AUTOSAR XML (schema 3.1.2)
package /Components/SWC_VSInfo
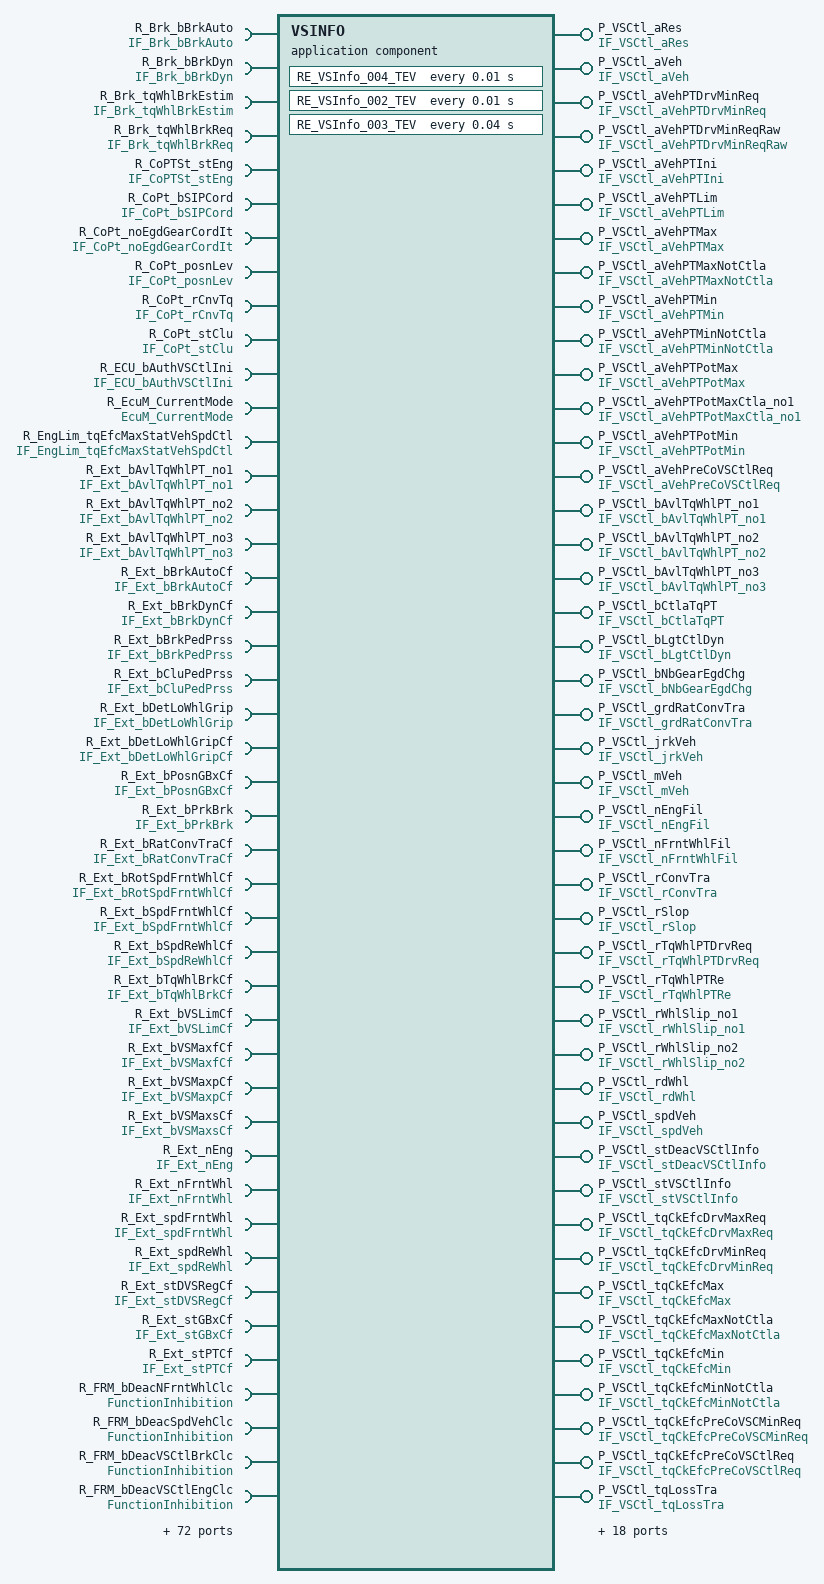
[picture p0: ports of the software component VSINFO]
  application software component type VSINFO  # VSInfo
    62 x provide port:
      P_VSCtl_aRes: unqueued-sender-com-spec{data-element=VSCtl_aRes, can-invalidate=false, init-value=ConstantValue}, provided-interface=IF_VSCtl_aRes
      P_VSCtl_aVeh: unqueued-sender-com-spec{data-element=VSCtl_aVeh, can-invalidate=false, init-value=C_SInt16_0}, provided-interface=IF_VSCtl_aVeh
      P_VSCtl_aVehPTDrvMinReq: unqueued-sender-com-spec{data-element=VSCtl_aVehPTDrvMinReq, can-invalidate=false, init-value=ConstantValue1}, provided-interface=IF_VSCtl_aVehPTDrvMinReq
      P_VSCtl_aVehPTDrvMinReqRaw: unqueued-sender-com-spec{data-element=VSCtl_aVehPTDrvMinReqRaw, can-invalidate=false, init-value=ConstantValue3}, provided-interface=IF_VSCtl_aVehPTDrvMinReqRaw
      P_VSCtl_aVehPTIni: unqueued-sender-com-spec{data-element=VSCtl_aVehPTIni, can-invalidate=false, init-value=C_SInt16_05}, provided-interface=IF_VSCtl_aVehPTIni
      P_VSCtl_aVehPTLim: unqueued-sender-com-spec{data-element=VSCtl_aVehPTLim, can-invalidate=false, init-value=ConstantValue7}, provided-interface=IF_VSCtl_aVehPTLim
      P_VSCtl_aVehPTMax: unqueued-sender-com-spec{data-element=VSCtl_aVehPTMax, can-invalidate=false, init-value=ConstantValue9}, provided-interface=IF_VSCtl_aVehPTMax
      P_VSCtl_aVehPTMaxNotCtla: unqueued-sender-com-spec{data-element=VSCtl_aVehPTMaxNotCtla, can-invalidate=false, init-value=ConstantValue11}, provided-interface=IF_VSCtl_aVehPTMaxNotCtla
      P_VSCtl_aVehPTMin: unqueued-sender-com-spec{data-element=VSCtl_aVehPTMin, can-invalidate=false, init-value=ConstantValue13}, provided-interface=IF_VSCtl_aVehPTMin
      P_VSCtl_aVehPTMinNotCtla: unqueued-sender-com-spec{data-element=VSCtl_aVehPTMinNotCtla, can-invalidate=false, init-value=ConstantValue15}, provided-interface=IF_VSCtl_aVehPTMinNotCtla
      P_VSCtl_aVehPTPotMax: unqueued-sender-com-spec{data-element=VSCtl_aVehPTPotMax, can-invalidate=false, init-value=ConstantValue17}, provided-interface=IF_VSCtl_aVehPTPotMax
      P_VSCtl_aVehPTPotMaxCtla_no1: unqueued-sender-com-spec{data-element=VSCtl_aVehPTPotMaxCtla_no1, can-invalidate=false, init-value=C_SInt16_10240}, provided-interface=IF_VSCtl_aVehPTPotMaxCtla_no1
      P_VSCtl_aVehPTPotMin: unqueued-sender-com-spec{data-element=VSCtl_aVehPTPotMin, can-invalidate=false, init-value=ConstantValue19}, provided-interface=IF_VSCtl_aVehPTPotMin
      P_VSCtl_aVehPreCoVSCtlReq: unqueued-sender-com-spec{data-element=VSCtl_aVehPreCoVSCtlReq, can-invalidate=false, init-value=ConstantValue21}, provided-interface=IF_VSCtl_aVehPreCoVSCtlReq
      P_VSCtl_bAvlTqWhlPT_no1: unqueued-sender-com-spec{data-element=VSCtl_bAvlTqWhlPT_no1, can-invalidate=false, init-value=C_Boolean_False}, provided-interface=IF_VSCtl_bAvlTqWhlPT_no1
      P_VSCtl_bAvlTqWhlPT_no2: unqueued-sender-com-spec{data-element=VSCtl_bAvlTqWhlPT_no2, can-invalidate=false, init-value=C_Boolean_False23}, provided-interface=IF_VSCtl_bAvlTqWhlPT_no2
      P_VSCtl_bAvlTqWhlPT_no3: unqueued-sender-com-spec{data-element=VSCtl_bAvlTqWhlPT_no3, can-invalidate=false, init-value=ConstantValue25}, provided-interface=IF_VSCtl_bAvlTqWhlPT_no3
      P_VSCtl_bCtlaTqPT: unqueued-sender-com-spec{data-element=VSCtl_bCtlaTqPT, can-invalidate=false, init-value=C_Boolean_False27}, provided-interface=IF_VSCtl_bCtlaTqPT
      P_VSCtl_bLgtCtlDyn: unqueued-sender-com-spec{data-element=VSCtl_bLgtCtlDyn, can-invalidate=false, init-value=C_Boolean_False29}, provided-interface=IF_VSCtl_bLgtCtlDyn
      P_VSCtl_bNbGearEgdChg: unqueued-sender-com-spec{data-element=VSCtl_bNbGearEgdChg, can-invalidate=false, init-value=C_Boolean_False31}, provided-interface=IF_VSCtl_bNbGearEgdChg
      P_VSCtl_grdRatConvTra: unqueued-sender-com-spec{data-element=VSCtl_grdRatConvTra, can-invalidate=false, init-value=C_SInt16_033}, provided-interface=IF_VSCtl_grdRatConvTra
      P_VSCtl_jrkVeh: unqueued-sender-com-spec{data-element=VSCtl_jrkVeh, can-invalidate=false, init-value=C_SInt16_035}, provided-interface=IF_VSCtl_jrkVeh
      P_VSCtl_mVeh: unqueued-sender-com-spec{data-element=VSCtl_mVeh, can-invalidate=false, init-value=ConstantValue37}, provided-interface=IF_VSCtl_mVeh
      P_VSCtl_nEngFil: unqueued-sender-com-spec{data-element=VSCtl_nEngFil, can-invalidate=false, init-value=C_UInt32_0}, provided-interface=IF_VSCtl_nEngFil
      P_VSCtl_nFrntWhlFil: unqueued-sender-com-spec{data-element=VSCtl_nFrntWhlFil, can-invalidate=false, init-value=C_UInt32_039}, provided-interface=IF_VSCtl_nFrntWhlFil
      P_VSCtl_rConvTra: unqueued-sender-com-spec{data-element=VSCtl_rConvTra, can-invalidate=false, init-value=C_UInt16_2560}, provided-interface=IF_VSCtl_rConvTra
      P_VSCtl_rSlop: unqueued-sender-com-spec{data-element=VSCtl_rSlop, can-invalidate=false, init-value=C_SInt16_041}, provided-interface=IF_VSCtl_rSlop
      P_VSCtl_rTqWhlPTDrvReq: unqueued-sender-com-spec{data-element=VSCtl_rTqWhlPTDrvReq, can-invalidate=false, init-value=C_UInt16_0}, provided-interface=IF_VSCtl_rTqWhlPTDrvReq
      P_VSCtl_rTqWhlPTRe: unqueued-sender-com-spec{data-element=VSCtl_rTqWhlPTRe, can-invalidate=false, init-value=C_UInt16_043}, provided-interface=IF_VSCtl_rTqWhlPTRe
      P_VSCtl_rWhlSlip_no1: unqueued-sender-com-spec{data-element=VSCtl_rWhlSlip_no1, can-invalidate=false, init-value=C_UInt16_045}, provided-interface=IF_VSCtl_rWhlSlip_no1
      P_VSCtl_rWhlSlip_no2: unqueued-sender-com-spec{data-element=VSCtl_rWhlSlip_no2, can-invalidate=false, init-value=C_UInt16_047}, provided-interface=IF_VSCtl_rWhlSlip_no2
      P_VSCtl_rdWhl: unqueued-sender-com-spec{data-element=VSCtl_rdWhl, can-invalidate=false, init-value=ConstantValue49}, provided-interface=IF_VSCtl_rdWhl
      P_VSCtl_spdVeh: unqueued-sender-com-spec{data-element=VSCtl_spdVeh, can-invalidate=false, init-value=ConstantValue51}, provided-interface=IF_VSCtl_spdVeh
      P_VSCtl_stDeacVSCtlInfo: unqueued-sender-com-spec{data-element=VSCtl_stDeacVSCtlInfo, can-invalidate=false, init-value=C_UInt8_32}, provided-interface=IF_VSCtl_stDeacVSCtlInfo
      P_VSCtl_stVSCtlInfo: unqueued-sender-com-spec{data-element=VSCtl_stVSCtlInfo, can-invalidate=false, init-value=ConstantValue53}, provided-interface=IF_VSCtl_stVSCtlInfo
      P_VSCtl_tqCkEfcDrvMaxReq: unqueued-sender-com-spec{data-element=VSCtl_tqCkEfcDrvMaxReq, can-invalidate=false, init-value=C_SInt16_32000}, provided-interface=IF_VSCtl_tqCkEfcDrvMaxReq
      P_VSCtl_tqCkEfcDrvMinReq: unqueued-sender-com-spec{data-element=VSCtl_tqCkEfcDrvMinReq, can-invalidate=false, init-value=C_SInt16_m32000}, provided-interface=IF_VSCtl_tqCkEfcDrvMinReq
      P_VSCtl_tqCkEfcMax: unqueued-sender-com-spec{data-element=VSCtl_tqCkEfcMax, can-invalidate=false, init-value=C_SInt16_3200055}, provided-interface=IF_VSCtl_tqCkEfcMax
      P_VSCtl_tqCkEfcMaxNotCtla: unqueued-sender-com-spec{data-element=VSCtl_tqCkEfcMaxNotCtla, can-invalidate=false, init-value=C_SInt16_057}, provided-interface=IF_VSCtl_tqCkEfcMaxNotCtla
      P_VSCtl_tqCkEfcMin: unqueued-sender-com-spec{data-element=VSCtl_tqCkEfcMin, can-invalidate=false, init-value=C_SInt16_m3200059}, provided-interface=IF_VSCtl_tqCkEfcMin
      P_VSCtl_tqCkEfcMinNotCtla: unqueued-sender-com-spec{data-element=VSCtl_tqCkEfcMinNotCtla, can-invalidate=false, init-value=C_SInt16_061}, provided-interface=IF_VSCtl_tqCkEfcMinNotCtla
      P_VSCtl_tqCkEfcPreCoVSCMinReq: unqueued-sender-com-spec{data-element=VSCtl_tqCkEfcPreCoVSCMinReq, can-invalidate=false, init-value=C_SInt16_m3200063}, provided-interface=IF_VSCtl_tqCkEfcPreCoVSCMinReq
      P_VSCtl_tqCkEfcPreCoVSCtlReq: unqueued-sender-com-spec{data-element=VSCtl_tqCkEfcPreCoVSCtlReq, can-invalidate=false, init-value=C_SInt16_m3200065}, provided-interface=IF_VSCtl_tqCkEfcPreCoVSCtlReq
      P_VSCtl_tqLossTra: unqueued-sender-com-spec{data-element=VSCtl_tqLossTra, can-invalidate=false, init-value=C_SInt16_067}, provided-interface=IF_VSCtl_tqLossTra
      P_VSCtl_tqWhlPTAplReq: unqueued-sender-com-spec{data-element=VSCtl_tqWhlPTAplReq, can-invalidate=false, init-value=C_SInt16_069}, provided-interface=IF_VSCtl_tqWhlPTAplReq
      P_VSCtl_tqWhlPTDrvMaxReq: unqueued-sender-com-spec{data-element=VSCtl_tqWhlPTDrvMaxReq, can-invalidate=false, init-value=C_SInt16_3200071}, provided-interface=IF_VSCtl_tqWhlPTDrvMaxReq
      P_VSCtl_tqWhlPTDrvMinReq: unqueued-sender-com-spec{data-element=VSCtl_tqWhlPTDrvMinReq, can-invalidate=false, init-value=C_SInt16_m3200073}, provided-interface=IF_VSCtl_tqWhlPTDrvMinReq
      P_VSCtl_tqWhlPTDrvMinReqRaw: unqueued-sender-com-spec{data-element=VSCtl_tqWhlPTDrvMinReqRaw, can-invalidate=false, init-value=C_SInt16_m3200075}, provided-interface=IF_VSCtl_tqWhlPTDrvMinReqRaw
      P_VSCtl_tqWhlPTMax: unqueued-sender-com-spec{data-element=VSCtl_tqWhlPTMax, can-invalidate=false, init-value=ConstantValue77}, provided-interface=IF_VSCtl_tqWhlPTMax
      P_VSCtl_tqWhlPTMaxNotCtla: unqueued-sender-com-spec{data-element=VSCtl_tqWhlPTMaxNotCtla, can-invalidate=false, init-value=C_SInt16_079}, provided-interface=IF_VSCtl_tqWhlPTMaxNotCtla
      P_VSCtl_tqWhlPTMin: unqueued-sender-com-spec{data-element=VSCtl_tqWhlPTMin, can-invalidate=false, init-value=ConstantValue81}, provided-interface=IF_VSCtl_tqWhlPTMin
      P_VSCtl_tqWhlPTMinNotCtla: unqueued-sender-com-spec{data-element=VSCtl_tqWhlPTMinNotCtla, can-invalidate=false, init-value=C_SInt16_083}, provided-interface=IF_VSCtl_tqWhlPTMinNotCtla
      P_VSCtl_tqWhlPTPotMax: unqueued-sender-com-spec{data-element=VSCtl_tqWhlPTPotMax, can-invalidate=false, init-value=ConstantValue85}, provided-interface=IF_VSCtl_tqWhlPTPotMax
      P_VSCtl_tqWhlPTPotMin: unqueued-sender-com-spec{data-element=VSCtl_tqWhlPTPotMin, can-invalidate=false, init-value=ConstantValue87}, provided-interface=IF_VSCtl_tqWhlPTPotMin
      P_VSCtl_tqWhlPTPotRawMax: unqueued-sender-com-spec{data-element=VSCtl_tqWhlPTPotRawMax, can-invalidate=false, init-value=C_SInt16_m3200089}, provided-interface=IF_VSCtl_tqWhlPTPotRawMax
      P_VSCtl_tqWhlPTPotRawMin: unqueued-sender-com-spec{data-element=VSCtl_tqWhlPTPotRawMin, can-invalidate=false, init-value=C_SInt16_m3200091}, provided-interface=IF_VSCtl_tqWhlPTPotRawMin
      P_VSCtl_tqWhlPTPreCoVSCMaxReq: unqueued-sender-com-spec{data-element=VSCtl_tqWhlPTPreCoVSCMaxReq, can-invalidate=false, init-value=C_SInt16_m3200093}, provided-interface=IF_VSCtl_tqWhlPTPreCoVSCMaxReq
      P_VSCtl_tqWhlPTPreCoVSCMinReq: unqueued-sender-com-spec{data-element=VSCtl_tqWhlPTPreCoVSCMinReq, can-invalidate=false, init-value=C_SInt16_m3200095}, provided-interface=IF_VSCtl_tqWhlPTPreCoVSCMinReq
      P_VSCtl_tqWhlPTPreCoVSCtlReq: unqueued-sender-com-spec{data-element=VSCtl_tqWhlPTPreCoVSCtlReq, can-invalidate=false, init-value=C_SInt16_m3200097}, provided-interface=IF_VSCtl_tqWhlPTPreCoVSCtlReq
      P_VSCtl_tqWhlPTReal: unqueued-sender-com-spec{data-element=VSCtl_tqWhlPTReal, can-invalidate=false, init-value=C_SInt16_099}, provided-interface=IF_VSCtl_tqWhlPTReal
      P_VSCtl_tqWhlThPTMin: unqueued-sender-com-spec{data-element=VSCtl_tqWhlThPTMin, can-invalidate=false, init-value=ConstantValue101}, provided-interface=IF_VSCtl_tqWhlThPTMin
      P_VSCtl_tqWhlThPTPotMin: unqueued-sender-com-spec{data-element=VSCtl_tqWhlThPTPotMin, can-invalidate=false, init-value=ConstantValue103}, provided-interface=IF_VSCtl_tqWhlThPTPotMin
    116 x require port:
      R_Brk_bBrkAuto: unqueued-receiver-com-spec{data-element=Brk_bBrkAuto, init-value=ConstantValue105, resync-time=0}, required-interface=IF_Brk_bBrkAuto
      R_Brk_bBrkDyn: unqueued-receiver-com-spec{data-element=Brk_bBrkDyn, init-value=C_Boolean_False107, resync-time=0}, required-interface=IF_Brk_bBrkDyn
      R_Brk_tqWhlBrkEstim: unqueued-receiver-com-spec{data-element=Brk_tqWhlBrkEstim, init-value=C_SInt16_m32000109, resync-time=0}, required-interface=IF_Brk_tqWhlBrkEstim
      R_Brk_tqWhlBrkReq: unqueued-receiver-com-spec{data-element=Brk_tqWhlBrkReq, init-value=C_SInt16_m32000111, resync-time=0}, required-interface=IF_Brk_tqWhlBrkReq
      R_CoPTSt_stEng: unqueued-receiver-com-spec{data-element=CoPTSt_stEng, init-value=ConstantValue113, resync-time=0}, required-interface=IF_CoPTSt_stEng
      R_CoPt_bSIPCord: unqueued-receiver-com-spec{data-element=CoPt_bSIPCord, init-value=ConstantValue115, resync-time=0}, required-interface=IF_CoPt_bSIPCord
      R_CoPt_noEgdGearCordIt: unqueued-receiver-com-spec{data-element=CoPt_noEgdGearCordIt, init-value=ConstantValue117, resync-time=0}, required-interface=IF_CoPt_noEgdGearCordIt
      R_CoPt_posnLev: unqueued-receiver-com-spec{data-element=CoPt_posnLev, init-value=ConstantValue119, resync-time=0}, required-interface=IF_CoPt_posnLev
      R_CoPt_rCnvTq: unqueued-receiver-com-spec{data-element=CoPt_rCnvTq, init-value=ConstantValue121, resync-time=0}, required-interface=IF_CoPt_rCnvTq
      R_CoPt_stClu: unqueued-receiver-com-spec{data-element=CoPt_stClu, init-value=ConstantValue123, resync-time=0}, required-interface=IF_CoPt_stClu
      R_ECU_bAuthVSCtlIni: unqueued-receiver-com-spec{data-element=ECU_bAuthVSCtlIni, init-value=C_Boolean_False125, resync-time=0}, required-interface=IF_ECU_bAuthVSCtlIni
      R_EcuM_CurrentMode: required-interface=EcuM_CurrentMode  # Requirement: 01552_09_00532-SSTG-C007(2)
      R_EngLim_tqEfcMaxStatVehSpdCtl: unqueued-receiver-com-spec{data-element=EngLim_tqEfcMaxStatVehSpdCtl, init-value=C_SInt16_m32000127, resync-time=0}, required-interface=IF_EngLim_tqEfcMaxStatVehSpdCtl
      R_Ext_bAvlTqWhlPT_no1: unqueued-receiver-com-spec{data-element=Ext_bAvlTqWhlPT_no1, init-value=C_Boolean_False129, resync-time=0}, required-interface=IF_Ext_bAvlTqWhlPT_no1
      R_Ext_bAvlTqWhlPT_no2: unqueued-receiver-com-spec{data-element=Ext_bAvlTqWhlPT_no2, init-value=C_Boolean_False131, resync-time=0}, required-interface=IF_Ext_bAvlTqWhlPT_no2
      R_Ext_bAvlTqWhlPT_no3: unqueued-receiver-com-spec{data-element=Ext_bAvlTqWhlPT_no3, init-value=C_Boolean_False133, resync-time=0}, required-interface=IF_Ext_bAvlTqWhlPT_no3
      R_Ext_bBrkAutoCf: unqueued-receiver-com-spec{data-element=Ext_bBrkAutoCf, init-value=C_Boolean_False135, resync-time=0}, required-interface=IF_Ext_bBrkAutoCf
      R_Ext_bBrkDynCf: unqueued-receiver-com-spec{data-element=Ext_bBrkDynCf, init-value=C_Boolean_False137, resync-time=0}, required-interface=IF_Ext_bBrkDynCf
      R_Ext_bBrkPedPrss: unqueued-receiver-com-spec{data-element=Ext_bBrkPedPrss, init-value=ConstantValue139, resync-time=0}, required-interface=IF_Ext_bBrkPedPrss
      R_Ext_bCluPedPrss: unqueued-receiver-com-spec{data-element=Ext_bCluPedPrss, init-value=ConstantValue141, resync-time=0}, required-interface=IF_Ext_bCluPedPrss
      R_Ext_bDetLoWhlGrip: unqueued-receiver-com-spec{data-element=Ext_bDetLoWhlGrip, init-value=C_Boolean_False143, resync-time=0}, required-interface=IF_Ext_bDetLoWhlGrip
      R_Ext_bDetLoWhlGripCf: unqueued-receiver-com-spec{data-element=Ext_bDetLoWhlGripCf, init-value=C_Boolean_False145, resync-time=0}, required-interface=IF_Ext_bDetLoWhlGripCf
      R_Ext_bPosnGBxCf: unqueued-receiver-com-spec{data-element=Ext_bPosnGBxCf, init-value=ConstantValue147, resync-time=0}, required-interface=IF_Ext_bPosnGBxCf
      R_Ext_bPrkBrk: unqueued-receiver-com-spec{data-element=Ext_bPrkBrk, init-value=C_Boolean_False149, resync-time=0}, required-interface=IF_Ext_bPrkBrk
      R_Ext_bRatConvTraCf: unqueued-receiver-com-spec{data-element=Ext_bRatConvTraCf, init-value=C_Boolean_False151, resync-time=0}, required-interface=IF_Ext_bRatConvTraCf
      R_Ext_bRotSpdFrntWhlCf: unqueued-receiver-com-spec{data-element=Ext_bRotSpdFrntWhlCf, init-value=C_Boolean_False153, resync-time=0}, required-interface=IF_Ext_bRotSpdFrntWhlCf
      R_Ext_bSpdFrntWhlCf: unqueued-receiver-com-spec{data-element=Ext_bSpdFrntWhlCf, init-value=C_Boolean_False155, resync-time=0}, required-interface=IF_Ext_bSpdFrntWhlCf
      R_Ext_bSpdReWhlCf: unqueued-receiver-com-spec{data-element=Ext_bSpdReWhlCf, init-value=C_Boolean_False157, resync-time=0}, required-interface=IF_Ext_bSpdReWhlCf
      R_Ext_bTqWhlBrkCf: unqueued-receiver-com-spec{data-element=Ext_bTqWhlBrkCf, init-value=C_Boolean_False159, resync-time=0}, required-interface=IF_Ext_bTqWhlBrkCf
      R_Ext_bVSLimCf: unqueued-receiver-com-spec{data-element=Ext_bVSLimCf, init-value=ConstantValue161, resync-time=0}, required-interface=IF_Ext_bVSLimCf
      R_Ext_bVSMaxfCf: unqueued-receiver-com-spec{data-element=Ext_bVSMaxfCf, init-value=ConstantValue163, resync-time=0}, required-interface=IF_Ext_bVSMaxfCf
      R_Ext_bVSMaxpCf: unqueued-receiver-com-spec{data-element=Ext_bVSMaxpCf, init-value=ConstantValue165, resync-time=0}, required-interface=IF_Ext_bVSMaxpCf
      R_Ext_bVSMaxsCf: unqueued-receiver-com-spec{data-element=Ext_bVSMaxsCf, init-value=ConstantValue167, resync-time=0}, required-interface=IF_Ext_bVSMaxsCf
      R_Ext_nEng: unqueued-receiver-com-spec{data-element=Ext_nEng, init-value=ConstantValue169, resync-time=0}, required-interface=IF_Ext_nEng
      R_Ext_nFrntWhl: unqueued-receiver-com-spec{data-element=Ext_nFrntWhl, init-value=C_UInt32_0171, resync-time=0}, required-interface=IF_Ext_nFrntWhl
      R_Ext_spdFrntWhl: unqueued-receiver-com-spec{data-element=Ext_spdFrntWhl, init-value=C_UInt16_0173, resync-time=0}, required-interface=IF_Ext_spdFrntWhl
      R_Ext_spdReWhl: unqueued-receiver-com-spec{data-element=Ext_spdReWhl, init-value=C_UInt16_0175, resync-time=0}, required-interface=IF_Ext_spdReWhl
      R_Ext_stDVSRegCf: unqueued-receiver-com-spec{data-element=Ext_stDVSRegCf, init-value=ConstantValue177, resync-time=0}, required-interface=IF_Ext_stDVSRegCf
      R_Ext_stGBxCf: unqueued-receiver-com-spec{data-element=Ext_stGBxCf, init-value=ConstantValue179, resync-time=0}, required-interface=IF_Ext_stGBxCf
      R_Ext_stPTCf: unqueued-receiver-com-spec{data-element=Ext_stPTCf, init-value=C_UInt8_0, resync-time=0}, required-interface=IF_Ext_stPTCf
      R_FRM_bDeacNFrntWhlClc: required-interface=FunctionInhibition
      R_FRM_bDeacSpdVehClc: required-interface=FunctionInhibition
      R_FRM_bDeacVSCtlBrkClc: required-interface=FunctionInhibition
      R_FRM_bDeacVSCtlEngClc: required-interface=FunctionInhibition
      R_FRM_bDeacVSCtlGrdLkClc: required-interface=FunctionInhibition
      R_FRM_bDeacVSCtlLoWhlGripClc: required-interface=FunctionInhibition
      R_FRM_bDeacVSCtlNoGearChgClc: required-interface=FunctionInhibition
      R_FRM_bDeacVSCtlPTClc: required-interface=FunctionInhibition
      R_FRM_bDeacVSCtlTraClc: required-interface=FunctionInhibition
      R_FRM_bDeacVSCtlVehClc: required-interface=FunctionInhibition
      R_FRM_bDeacVSCtlWhlSlipClc: required-interface=FunctionInhibition
      R_FRM_bDeacVSCtlrTqWhlPTReClc: required-interface=FunctionInhibition
      R_FRM_bRcvVSCtlSpdFrntWhl: required-interface=FunctionInhibition
      R_FRM_bRcvVSCtlSpdReWhl: required-interface=FunctionInhibition
      R_FRM_bRcvVSCtlrConvTra_Ext: required-interface=FunctionInhibition
      R_FRM_bRcvVSCtlrConvTra_Int1: required-interface=FunctionInhibition
      R_FRM_bRcvVSCtlrConvTra_Int2: required-interface=FunctionInhibition
      R_InjSys_bFuCutOff: unqueued-receiver-com-spec{data-element=InjSys_bFuCutOff, init-value=ConstantValue181, resync-time=0}, required-interface=IF_InjSys_bFuCutOff
      R_PtLim_tqWhlPTMaxCtla: unqueued-receiver-com-spec{data-element=PtLim_tqWhlPTMaxCtla, init-value=C_SInt16_m8000, resync-time=0}, required-interface=IF_PtLim_tqWhlPTMaxCtla
      R_PtLim_tqWhlPTMaxNotCtla: unqueued-receiver-com-spec{data-element=PtLim_tqWhlPTMaxNotCtla, init-value=C_SInt16_m8000183, resync-time=0}, required-interface=IF_PtLim_tqWhlPTMaxNotCtla
      R_PtLim_tqWhlPTMinCtla: unqueued-receiver-com-spec{data-element=PtLim_tqWhlPTMinCtla, init-value=C_SInt16_m8000185, resync-time=0}, required-interface=IF_PtLim_tqWhlPTMinCtla
      R_PtLim_tqWhlPTMinNotCtla: unqueued-receiver-com-spec{data-element=PtLim_tqWhlPTMinNotCtla, init-value=C_SInt16_m8000187, resync-time=0}, required-interface=IF_PtLim_tqWhlPTMinNotCtla
      R_PtLim_tqWhlPTPotMaxCtla_no1: unqueued-receiver-com-spec{data-element=PtLim_tqWhlPTPotMaxCtla_no1, init-value=C_SInt16_m8000189, resync-time=0}, required-interface=IF_PtLim_tqWhlPTPotMaxCtla_no1
      R_PtLim_tqWhlPTPotMaxCtla_no2: unqueued-receiver-com-spec{data-element=PtLim_tqWhlPTPotMaxCtla_no2, init-value=C_SInt16_m8000191, resync-time=0}, required-interface=IF_PtLim_tqWhlPTPotMaxCtla_no2
      R_PtLim_tqWhlPTPotMinCtla: unqueued-receiver-com-spec{data-element=PtLim_tqWhlPTPotMinCtla, init-value=C_SInt16_m8000193, resync-time=0}, required-interface=IF_PtLim_tqWhlPTPotMinCtla
      R_PtLim_tqWhlThPTMin: unqueued-receiver-com-spec{data-element=PtLim_tqWhlThPTMin, init-value=C_SInt16_m8000195, resync-time=0}, required-interface=IF_PtLim_tqWhlThPTMin
      R_PtLim_tqWhlThPTPotMin: unqueued-receiver-com-spec{data-element=PtLim_tqWhlThPTPotMin, init-value=C_SInt16_m8000197, resync-time=0}, required-interface=IF_PtLim_tqWhlThPTPotMin
      R_TqCmp_tqCnvLoss: unqueued-receiver-com-spec{data-element=TqCmp_tqCnvLoss, init-value=ConstantValue199, resync-time=0}, required-interface=IF_TqCmp_tqCnvLoss
      R_TqCmp_tqSumLossCmp: unqueued-receiver-com-spec{data-element=TqCmp_tqSumLossCmp, init-value=ConstantValue201, resync-time=0}, required-interface=IF_TqCmp_tqSumLossCmp
      R_TqDem_tqCkEfc: unqueued-receiver-com-spec{data-element=TqDem_tqCkEfc, init-value=ConstantValue203, resync-time=0}, required-interface=IF_TqDem_tqCkEfc
      R_TqDem_tqCkEfcMax: unqueued-receiver-com-spec{data-element=TqDem_tqCkEfcMax, init-value=ConstantValue205, resync-time=0}, required-interface=IF_TqDem_tqCkEfcMax
      R_TqDem_tqCkEfcMin: unqueued-receiver-com-spec{data-element=TqDem_tqCkEfcMin, init-value=ConstantValue207, resync-time=0}, required-interface=IF_TqDem_tqCkEfcMin
      R_TqDem_tqWhlPTDrvMaxReq: unqueued-receiver-com-spec{data-element=TqDem_tqWhlPTDrvMaxReq, init-value=C_SInt16_m8000209, resync-time=0}, required-interface=IF_TqDem_tqWhlPTDrvMaxReq
      R_TqDem_tqWhlPTDrvMinReq: unqueued-receiver-com-spec{data-element=TqDem_tqWhlPTDrvMinReq, init-value=C_SInt16_m8000211, resync-time=0}, required-interface=IF_TqDem_tqWhlPTDrvMinReq
      R_TqDem_tqWhlPTDrvMinReqRaw: unqueued-receiver-com-spec{data-element=TqDem_tqWhlPTDrvMinReqRaw, init-value=C_SInt16_m8000213, resync-time=0}, required-interface=IF_TqDem_tqWhlPTDrvMinReqRaw
      R_TqDem_tqWhlPTDrvReq: unqueued-receiver-com-spec{data-element=TqDem_tqWhlPTDrvReq, init-value=C_SInt16_m8000215, resync-time=0}, required-interface=IF_TqDem_tqWhlPTDrvReq
      R_TqDem_tqWhlPTPreCoVSCMaxReq: unqueued-receiver-com-spec{data-element=TqDem_tqWhlPTPreCoVSCMaxReq, init-value=C_SInt16_m8000217, resync-time=0}, required-interface=IF_TqDem_tqWhlPTPreCoVSCMaxReq
      R_TqDem_tqWhlPTPreCoVSCMinReq: unqueued-receiver-com-spec{data-element=TqDem_tqWhlPTPreCoVSCMinReq, init-value=C_SInt16_m8000219, resync-time=0}, required-interface=IF_TqDem_tqWhlPTPreCoVSCMinReq
      R_TqDem_tqWhlPTPreCoVSCtlReq: unqueued-receiver-com-spec{data-element=TqDem_tqWhlPTPreCoVSCtlReq, init-value=C_SInt16_m8000221, resync-time=0}, required-interface=IF_TqDem_tqWhlPTPreCoVSCtlReq
      R_TqSys_tqCkEfcMinFeas: unqueued-receiver-com-spec{data-element=TqSys_tqCkEfcMinFeas, init-value=ConstantValue223, resync-time=0}, required-interface=IF_TqSys_tqCkEfcMinFeas
      R_TqSys_tqCkEfcReq: unqueued-receiver-com-spec{data-element=TqSys_tqCkEfcReq, init-value=ConstantValue225, resync-time=0}, required-interface=IF_TqSys_tqCkEfcReq
      R_TqSys_tqCkEngReal: unqueued-receiver-com-spec{data-element=TqSys_tqCkEngReal, init-value=ConstantValue227, resync-time=0}, required-interface=IF_TqSys_tqCkEngReal
      R_UCE_stWkuMainRelSt: required-interface=IF_UCE_stWkuMainRelSt  # Requirement: 01552_09_00532-SSTG-C011(1)
      R_VSCtl_RatConvTraClc: required-interface=DiagnosticMonitor
      R_VSCtl_SpdVehClc: required-interface=DiagnosticMonitor
      R_VSCtl_aVehReq: unqueued-receiver-com-spec{data-element=VSCtl_aVehReq, init-value=ConstantValue229, resync-time=0}, required-interface=IF_VSCtl_aVehReq
      R_VSCtl_bAvlTqWhlPT_no3: unqueued-receiver-com-spec{data-element=VSCtl_bAvlTqWhlPT_no3, init-value=ConstantValue231, resync-time=0}, required-interface=IF_VSCtl_bAvlTqWhlPT_no3
      R_VSCtl_bCtlEfc_tqCkEfcMax: unqueued-receiver-com-spec{data-element=VSCtl_bCtlEfc_tqCkEfcMax, init-value=ConstantValue233, resync-time=0}, required-interface=IF_VSCtl_bCtlEfc_tqCkEfcMax
      R_VSCtl_bCtlEfc_tqWhlPTMax: unqueued-receiver-com-spec{data-element=VSCtl_bCtlEfc_tqWhlPTMax, init-value=ConstantValue235, resync-time=0}, required-interface=IF_VSCtl_bCtlEfc_tqWhlPTMax
      R_VSCtl_mVeh: unqueued-receiver-com-spec{data-element=VSCtl_mVeh, init-value=ConstantValue237, resync-time=0}, required-interface=IF_VSCtl_mVeh
      R_VSCtl_rSlop: unqueued-receiver-com-spec{data-element=VSCtl_rSlop, init-value=C_SInt16_m2560, resync-time=0}, required-interface=IF_VSCtl_rSlop
      R_VSCtl_rTqWhlPTRe: unqueued-receiver-com-spec{data-element=VSCtl_rTqWhlPTRe, init-value=C_UInt16_0239, resync-time=0}, required-interface=IF_VSCtl_rTqWhlPTRe
      R_VSCtl_rdWhl: unqueued-receiver-com-spec{data-element=VSCtl_rdWhl, init-value=ConstantValue241, resync-time=0}, required-interface=IF_VSCtl_rdWhl
      R_VSCtl_spdVeh: unqueued-receiver-com-spec{data-element=VSCtl_spdVeh, init-value=ConstantValue243, resync-time=0}, required-interface=IF_VSCtl_spdVeh
      R_VSCtl_tqWhlPTAplReq: unqueued-receiver-com-spec{data-element=VSCtl_tqWhlPTAplReq, init-value=C_SInt16_m8000245, resync-time=0}, required-interface=IF_VSCtl_tqWhlPTAplReq
      R_VSCtl_tqWhlPTDrvMinReq: unqueued-receiver-com-spec{data-element=VSCtl_tqWhlPTDrvMinReq, init-value=C_SInt16_m32000247, resync-time=0}, required-interface=IF_VSCtl_tqWhlPTDrvMinReq
      R_VSCtl_tqWhlPTDrvMinReqRaw: unqueued-receiver-com-spec{data-element=VSCtl_tqWhlPTDrvMinReqRaw, init-value=C_SInt16_m32000249, resync-time=0}, required-interface=IF_VSCtl_tqWhlPTDrvMinReqRaw
      R_VSCtl_tqWhlPTMax: unqueued-receiver-com-spec{data-element=VSCtl_tqWhlPTMax, init-value=ConstantValue251, resync-time=0}, required-interface=IF_VSCtl_tqWhlPTMax
      R_VSCtl_tqWhlPTMaxNotCtla: unqueued-receiver-com-spec{data-element=VSCtl_tqWhlPTMaxNotCtla, init-value=C_SInt16_m32000253, resync-time=0}, required-interface=IF_VSCtl_tqWhlPTMaxNotCtla
      R_VSCtl_tqWhlPTMin: unqueued-receiver-com-spec{data-element=VSCtl_tqWhlPTMin, init-value=ConstantValue255, resync-time=0}, required-interface=IF_VSCtl_tqWhlPTMin
      R_VSCtl_tqWhlPTMinNotCtla: unqueued-receiver-com-spec{data-element=VSCtl_tqWhlPTMinNotCtla, init-value=C_SInt16_m32000257, resync-time=0}, required-interface=IF_VSCtl_tqWhlPTMinNotCtla
      R_VSCtl_tqWhlPTPotMax: unqueued-receiver-com-spec{data-element=VSCtl_tqWhlPTPotMax, init-value=ConstantValue259, resync-time=0}, required-interface=IF_VSCtl_tqWhlPTPotMax
      R_VSCtl_tqWhlPTPotMin: unqueued-receiver-com-spec{data-element=VSCtl_tqWhlPTPotMin, init-value=ConstantValue261, resync-time=0}, required-interface=IF_VSCtl_tqWhlPTPotMin
      R_VSCtl_tqWhlPTPreCoVSCtlReq: unqueued-receiver-com-spec{data-element=VSCtl_tqWhlPTPreCoVSCtlReq, init-value=C_SInt16_m32000263, resync-time=0}, required-interface=IF_VSCtl_tqWhlPTPreCoVSCtlReq
      R_VSCtl_tqWhlPTReal: unqueued-receiver-com-spec{data-element=VSCtl_tqWhlPTReal, init-value=C_SInt16_m8000265, resync-time=0}, required-interface=IF_VSCtl_tqWhlPTReal
      R_VSCtl_tqWhlPotMaxRsvHiThd: unqueued-receiver-com-spec{data-element=VSCtl_tqWhlPotMaxRsvHiThd, init-value=ConstantValue267, resync-time=0}, required-interface=IF_VSCtl_tqWhlPotMaxRsvHiThd
      R_VSCtl_tqWhlPotMaxRsvLoThd: unqueued-receiver-com-spec{data-element=VSCtl_tqWhlPotMaxRsvLoThd, init-value=ConstantValue269, resync-time=0}, required-interface=IF_VSCtl_tqWhlPotMaxRsvLoThd
      R_VSCtl_tqWhlPotMinRsvHiThd: unqueued-receiver-com-spec{data-element=VSCtl_tqWhlPotMinRsvHiThd, init-value=ConstantValue271, resync-time=0}, required-interface=IF_VSCtl_tqWhlPotMinRsvHiThd
      R_VSCtl_tqWhlPotMinRsvLoThd: unqueued-receiver-com-spec{data-element=VSCtl_tqWhlPotMinRsvLoThd, init-value=ConstantValue273, resync-time=0}, required-interface=IF_VSCtl_tqWhlPotMinRsvLoThd
      R_VSInfo_GetTimer_1ms_U32: required-interface=IF_CS_FRunTime_1MS_U32
      R_VehEst_bCtlTqWhlPT: unqueued-receiver-com-spec{data-element=VehEst_bCtlTqWhlPT, init-value=C_Boolean_False275, resync-time=0}, required-interface=IF_VehEst_bCtlTqWhlPT
      R_VehEst_rTqWhlPTRe: unqueued-receiver-com-spec{data-element=VehEst_rTqWhlPTRe, init-value=C_UInt16_0277, resync-time=0}, required-interface=IF_VehEst_rTqWhlPTRe
      R_VehEst_tqWhlPTRealEstim: unqueued-receiver-com-spec{data-element=VehEst_tqWhlPTRealEstim, init-value=C_SInt16_m8000279, resync-time=0}, required-interface=IF_VehEst_tqWhlPTRealEstim
      R_VehEst_tqWhlPTReq: unqueued-receiver-com-spec{data-element=VehEst_tqWhlPTReq, init-value=C_SInt16_m8000281, resync-time=0}, required-interface=IF_VehEst_tqWhlPTReq
      R_Veh_spdVeh: unqueued-receiver-com-spec{data-element=Veh_spdVeh, init-value=ConstantValue283, resync-time=0}, required-interface=IF_Veh_spdVeh
      R_Ext_bCtlCmdPTTqCf: unqueued-receiver-com-spec{data-element=Ext_bCtlCmdPTTqCf, init-value=ConstantValue285, resync-time=0}, required-interface=IF_Ext_bCtlCmdPTTqCf  # R_Ext_bVSMaxpCf
  167 x constant specification:
    C_Boolean_False
      value:
        boolean literal C_Boolean_False: type=DT_VSCtl_bAvlTqWhlPT_no1, value=false
    C_Boolean_False107
      value:
        boolean literal C_Boolean_False107: type=DT_Brk_bBrkDyn, value=false
    C_Boolean_False125
      value:
        boolean literal C_Boolean_False125: type=DT_ECU_bAuthVSCtlIni, value=false
    C_Boolean_False129
      value:
        boolean literal C_Boolean_False129: type=DT_Ext_bAvlTqWhlPT_no1, value=false
    C_Boolean_False131
      value:
        boolean literal C_Boolean_False131: type=DT_Ext_bAvlTqWhlPT_no2, value=false
    C_Boolean_False133
      value:
        boolean literal C_Boolean_False133: type=DT_Ext_bAvlTqWhlPT_no3, value=false
    C_Boolean_False135
      value:
        boolean literal C_Boolean_False135: type=DT_Ext_bBrkAutoCf, value=false
    C_Boolean_False137
      value:
        boolean literal C_Boolean_False137: type=DT_Ext_bBrkDynCf, value=false
    C_Boolean_False143
      value:
        boolean literal C_Boolean_False143: type=DT_Ext_bDetLoWhlGrip, value=false
    C_Boolean_False145
      value:
        boolean literal C_Boolean_False145: type=DT_Ext_bDetLoWhlGripCf, value=false
    C_Boolean_False149
      value:
        boolean literal C_Boolean_False149: type=DT_Ext_bPrkBrk, value=false
    C_Boolean_False151
      value:
        boolean literal C_Boolean_False151: type=DT_Ext_bRatConvTraCf, value=false
    C_Boolean_False153
      value:
        boolean literal C_Boolean_False153: type=DT_Ext_bRotSpdFrntWhlCf, value=false
    C_Boolean_False155
      value:
        boolean literal C_Boolean_False155: type=DT_Ext_bSpdFrntWhlCf, value=false
    C_Boolean_False157
      value:
        boolean literal C_Boolean_False157: type=DT_Ext_bSpdReWhlCf, value=false
    C_Boolean_False159
      value:
        boolean literal C_Boolean_False159: type=DT_Ext_bTqWhlBrkCf, value=false
    C_Boolean_False23
      value:
        boolean literal C_Boolean_False23: type=DT_VSCtl_bAvlTqWhlPT_no2, value=false
    C_Boolean_False27
      value:
        boolean literal C_Boolean_False27: type=DT_VSCtl_bCtlaTqPT, value=false
    C_Boolean_False275
      value:
        boolean literal C_Boolean_False275: type=DT_VehEst_bCtlTqWhlPT, value=false
    C_Boolean_False29
      value:
        boolean literal C_Boolean_False29: type=DT_VSCtl_bLgtCtlDyn, value=false
    C_Boolean_False31
      value:
        boolean literal C_Boolean_False31: type=DT_VSCtl_bNbGearEgdChg, value=false
    C_SInt16_0
      value:
        integer literal C_SInt16_0: type=DT_VSCtl_aVeh, value=0
    C_SInt16_0287
      value:
        integer literal C_SInt16_0287: type=DT_VSCtl_aAero, value=0
    C_SInt16_0291
      value:
        integer literal C_SInt16_0291: type=DT_VSCtl_tqWhlPTIni, value=0
    C_SInt16_0297
      value:
        integer literal C_SInt16_0297: type=DT_VSCtl_tqWhlBrkEstim, value=0
    C_SInt16_0299
      value:
        integer literal C_SInt16_0299: type=DT_VSCtl_tqWhlBrkReq, value=0
    C_SInt16_033
      value:
        integer literal C_SInt16_033: type=DT_VSCtl_grdRatConvTra, value=0
    C_SInt16_035
      value:
        integer literal C_SInt16_035: type=DT_VSCtl_jrkVeh, value=0
    C_SInt16_041
      value:
        integer literal C_SInt16_041: type=DT_VSCtl_rSlop, value=0
    C_SInt16_05
      value:
        integer literal C_SInt16_05: type=DT_VSCtl_aVehPTIni, value=0
    C_SInt16_057
      value:
        integer literal C_SInt16_057: type=DT_VSCtl_tqCkEfcMaxNotCtla, value=0
    C_SInt16_061
      value:
        integer literal C_SInt16_061: type=DT_VSCtl_tqCkEfcMinNotCtla, value=0
    C_SInt16_067
      value:
        integer literal C_SInt16_067: type=DT_VSCtl_tqLossTra, value=0
    C_SInt16_069
      value:
        integer literal C_SInt16_069: type=DT_VSCtl_tqWhlPTAplReq, value=0
    C_SInt16_079
      value:
        integer literal C_SInt16_079: type=DT_VSCtl_tqWhlPTMaxNotCtla, value=0
    C_SInt16_083
      value:
        integer literal C_SInt16_083: type=DT_VSCtl_tqWhlPTMinNotCtla, value=0
    C_SInt16_099
      value:
        integer literal C_SInt16_099: type=DT_VSCtl_tqWhlPTReal, value=0
    C_SInt16_10240
      value:
        integer literal C_SInt16_10240: type=DT_VSCtl_aVehPTPotMaxCtla_no1, value=10240
    C_SInt16_32000
      value:
        integer literal C_SInt16_32000: type=DT_VSCtl_tqCkEfcDrvMaxReq, value=32000
    C_SInt16_32000295
      value:
        integer literal C_SInt16_32000295: type=DT_VSCtl_tqWhlPTPotMaxCtla_no1, value=32000
    C_SInt16_3200055
      value:
        integer literal C_SInt16_3200055: type=DT_VSCtl_tqCkEfcMax, value=32000
    C_SInt16_3200071
      value:
        integer literal C_SInt16_3200071: type=DT_VSCtl_tqWhlPTDrvMaxReq, value=32000
    C_SInt16_m2560
      value:
        integer literal C_SInt16_m2560: type=DT_VSCtl_rSlop, value=0
    C_SInt16_m32000
      value:
        integer literal C_SInt16_m32000: type=DT_VSCtl_tqCkEfcDrvMinReq, value=-32000
    C_SInt16_m32000109
      value:
        integer literal C_SInt16_m32000109: type=DT_Brk_tqWhlBrkEstim, value=0
    C_SInt16_m32000111
      value:
        integer literal C_SInt16_m32000111: type=DT_Brk_tqWhlBrkReq, value=0
    C_SInt16_m32000127
      value:
        integer literal C_SInt16_m32000127: type=DT_EngLim_tqEfcMaxStatVehSpdCtl, value=32000
    C_SInt16_m32000247
      value:
        integer literal C_SInt16_m32000247: type=DT_VSCtl_tqWhlPTDrvMinReq, value=0
    C_SInt16_m32000249
      value:
        integer literal C_SInt16_m32000249: type=DT_VSCtl_tqWhlPTDrvMinReqRaw, value=0
    C_SInt16_m32000253
      value:
        integer literal C_SInt16_m32000253: type=DT_VSCtl_tqWhlPTMaxNotCtla, value=0
    C_SInt16_m32000257
      value:
        integer literal C_SInt16_m32000257: type=DT_VSCtl_tqWhlPTMinNotCtla, value=0
    C_SInt16_m32000263
      value:
        integer literal C_SInt16_m32000263: type=DT_VSCtl_tqWhlPTPreCoVSCtlReq, value=0
    C_SInt16_m32000305
      value:
        integer literal C_SInt16_m32000305: type=DT_VSCtl_tqWhlPTLim, value=-32000
    C_SInt16_m3200059
      value:
        integer literal C_SInt16_m3200059: type=DT_VSCtl_tqCkEfcMin, value=-32000
    C_SInt16_m3200063
      value:
        integer literal C_SInt16_m3200063: type=DT_VSCtl_tqCkEfcPreCoVSCMinReq, value=-32000
    C_SInt16_m3200065
      value:
        integer literal C_SInt16_m3200065: type=DT_VSCtl_tqCkEfcPreCoVSCtlReq, value=4000
    C_SInt16_m3200073
      value:
        integer literal C_SInt16_m3200073: type=DT_VSCtl_tqWhlPTDrvMinReq, value=0
    C_SInt16_m3200075
      value:
        integer literal C_SInt16_m3200075: type=DT_VSCtl_tqWhlPTDrvMinReqRaw, value=0
    C_SInt16_m3200089
      value:
        integer literal C_SInt16_m3200089: type=DT_VSCtl_tqWhlPTPotRawMax, value=-32000
    C_SInt16_m3200091
      value:
        integer literal C_SInt16_m3200091: type=DT_VSCtl_tqWhlPTPotRawMin, value=-32000
    C_SInt16_m3200093
      value:
        integer literal C_SInt16_m3200093: type=DT_VSCtl_tqWhlPTPreCoVSCMaxReq, value=-32000
    C_SInt16_m3200095
      value:
        integer literal C_SInt16_m3200095: type=DT_VSCtl_tqWhlPTPreCoVSCMinReq, value=-32000
    C_SInt16_m3200097
      value:
        integer literal C_SInt16_m3200097: type=DT_VSCtl_tqWhlPTPreCoVSCtlReq, value=0
    C_SInt16_m8000
      value:
        integer literal C_SInt16_m8000: type=DT_PtLim_tqWhlPTMaxCtla, value=0
    C_SInt16_m8000183
      value:
        integer literal C_SInt16_m8000183: type=DT_PtLim_tqWhlPTMaxNotCtla, value=0
    C_SInt16_m8000185
      value:
        integer literal C_SInt16_m8000185: type=DT_PtLim_tqWhlPTMinCtla, value=0
    C_SInt16_m8000187
      value:
        integer literal C_SInt16_m8000187: type=DT_PtLim_tqWhlPTMinNotCtla, value=0
    C_SInt16_m8000189
      value:
        integer literal C_SInt16_m8000189: type=DT_PtLim_tqWhlPTPotMaxCtla_no1, value=0
    C_SInt16_m8000191
      value:
        integer literal C_SInt16_m8000191: type=DT_PtLim_tqWhlPTPotMaxCtla_no2, value=0
    C_SInt16_m8000193
      value:
        integer literal C_SInt16_m8000193: type=DT_PtLim_tqWhlPTPotMinCtla, value=0
    C_SInt16_m8000195
      value:
        integer literal C_SInt16_m8000195: type=DT_PtLim_tqWhlThPTMin, value=0
    C_SInt16_m8000197
      value:
        integer literal C_SInt16_m8000197: type=DT_PtLim_tqWhlThPTPotMin, value=0
    C_SInt16_m8000209
      value:
        integer literal C_SInt16_m8000209: type=DT_TqDem_tqWhlPTDrvMaxReq, value=0
    C_SInt16_m8000211
      value:
        integer literal C_SInt16_m8000211: type=DT_TqDem_tqWhlPTDrvMinReq, value=0
    C_SInt16_m8000213
      value:
        integer literal C_SInt16_m8000213: type=DT_TqDem_tqWhlPTDrvMinReqRaw, value=0
    C_SInt16_m8000215
      value:
        integer literal C_SInt16_m8000215: type=DT_TqDem_tqWhlPTDrvReq, value=0
    C_SInt16_m8000217
      value:
        integer literal C_SInt16_m8000217: type=DT_TqDem_tqWhlPTPreCoVSCMaxReq, value=0
    C_SInt16_m8000219
      value:
        integer literal C_SInt16_m8000219: type=DT_TqDem_tqWhlPTPreCoVSCMinReq, value=0
    C_SInt16_m8000221
      value:
        integer literal C_SInt16_m8000221: type=DT_TqDem_tqWhlPTPreCoVSCtlReq, value=0
    C_SInt16_m8000245
      value:
        integer literal C_SInt16_m8000245: type=DT_VSCtl_tqWhlPTAplReq, value=0
    C_SInt16_m8000265
      value:
        integer literal C_SInt16_m8000265: type=DT_VSCtl_tqWhlPTReal, value=0
    C_SInt16_m8000279
      value:
        integer literal C_SInt16_m8000279: type=DT_VehEst_tqWhlPTRealEstim, value=0
    C_SInt16_m8000281
      value:
        integer literal C_SInt16_m8000281: type=DT_VehEst_tqWhlPTReq, value=0
    C_UInt16_0
      value:
        integer literal C_UInt16_0: type=DT_VSCtl_rTqWhlPTDrvReq, value=0
    C_UInt16_0173
      value:
        integer literal C_UInt16_0173: type=DT_Ext_spdFrntWhl, value=0
    C_UInt16_0175
      value:
        integer literal C_UInt16_0175: type=DT_Ext_spdReWhl, value=0
    C_UInt16_0239
      value:
        integer literal C_UInt16_0239: type=DT_VSCtl_rTqWhlPTRe, value=0
    C_UInt16_0277
      value:
        integer literal C_UInt16_0277: type=DT_VehEst_rTqWhlPTRe, value=0
    C_UInt16_0307
      value:
        integer literal C_UInt16_0307: type=DT_VSCtl_spdVehRef, value=0
    C_UInt16_043
      value:
        integer literal C_UInt16_043: type=DT_VSCtl_rTqWhlPTRe, value=0
    C_UInt16_045
      value:
        integer literal C_UInt16_045: type=DT_VSCtl_rWhlSlip_no1, value=0
    C_UInt16_047
      value:
        integer literal C_UInt16_047: type=DT_VSCtl_rWhlSlip_no2, value=0
    C_UInt16_2560
      value:
        integer literal C_UInt16_2560: type=DT_VSCtl_rConvTra, value=2560
    C_UInt32_0
      value:
        integer literal C_UInt32_0: type=DT_VSCtl_nEngFil, value=0
    C_UInt32_0171
      value:
        integer literal C_UInt32_0171: type=DT_Ext_nFrntWhl, value=0
    C_UInt32_039
      value:
        integer literal C_UInt32_039: type=DT_VSCtl_nFrntWhlFil, value=0
    C_UInt8_0
      value:
        integer literal C_UInt8_0: type=DT_Ext_stPTCf, value=0
    C_UInt8_0289
      value:
        integer literal C_UInt8_0289: type=DT_VSCtl_stVehInfo, value=0
    C_UInt8_0293
      value:
        integer literal C_UInt8_0293: type=DT_VSCtl_stGrdLkInfo, value=0
    C_UInt8_0301
      value:
        integer literal C_UInt8_0301: type=DT_VSCtl_stPTInfo, value=0
    C_UInt8_0303
      value:
        integer literal C_UInt8_0303: type=DT_VSCtl_stDiagSpdVeh, value=0
    C_UInt8_32
      value:
        integer literal C_UInt8_32: type=DT_VSCtl_stDeacVSCtlInfo, value=32
    ConstantValue
      value:
        integer literal ConstantValue: type=DT_VSCtl_aRes, value=0
    ConstantValue1
      value:
        integer literal ConstantValue1: type=DT_VSCtl_aVehPTDrvMinReq, value=0
    ConstantValue101
      value:
        integer literal ConstantValue101: type=DT_VSCtl_tqWhlThPTMin, value=0
    ConstantValue103
      value:
        integer literal ConstantValue103: type=DT_VSCtl_tqWhlThPTPotMin, value=0
    ConstantValue105
      value:
        boolean literal ConstantValue105: type=DT_Brk_bBrkAuto, value=false
    ConstantValue11
      value:
        integer literal ConstantValue11: type=DT_VSCtl_aVehPTMaxNotCtla, value=0
    ConstantValue113
      value:
        integer literal ConstantValue113: type=DT_CoPTSt_stEng, value=1
    ConstantValue115
      value:
        boolean literal ConstantValue115: type=DT_CoPt_bSIPCord, value=false
    ConstantValue117
      value:
        integer literal ConstantValue117: type=DT_CoPt_noEgdGearCordIt, value=0
    ConstantValue119
      value:
        integer literal ConstantValue119: type=DT_CoPt_posnLev, value=0
    ConstantValue121
      value:
        integer literal ConstantValue121: type=DT_CoPt_rCnvTq, value=1
    ConstantValue123
      value:
        integer literal ConstantValue123: type=DT_CoPt_stClu, value=0
    ConstantValue13
      value:
        integer literal ConstantValue13: type=DT_VSCtl_aVehPTMin, value=0
    ConstantValue139
      value:
        boolean literal ConstantValue139: type=DT_Ext_bBrkPedPrss, value=false
    ConstantValue141
      value:
        boolean literal ConstantValue141: type=DT_Ext_bCluPedPrss, value=false
    ConstantValue147
      value:
        boolean literal ConstantValue147: type=DT_Ext_bPosnGBxCf, value=false
    ConstantValue15
      value:
        integer literal ConstantValue15: type=DT_VSCtl_aVehPTMinNotCtla, value=0
    ConstantValue161
      value:
        boolean literal ConstantValue161: type=DT_Ext_bVSLimCf, value=false
    ConstantValue163
      value:
        boolean literal ConstantValue163: type=DT_Ext_bVSMaxfCf, value=false
    ConstantValue165
      value:
        boolean literal ConstantValue165: type=DT_Ext_bVSMaxpCf, value=false
    ConstantValue167
      value:
        boolean literal ConstantValue167: type=DT_Ext_bVSMaxsCf, value=false
    ConstantValue169
      value:
        integer literal ConstantValue169: type=DT_Ext_nEng, value=0
    ConstantValue17
      value:
        integer literal ConstantValue17: type=DT_VSCtl_aVehPTPotMax, value=0
    ConstantValue177
      value:
        integer literal ConstantValue177: type=DT_Ext_stDVSRegCf, value=0
    ConstantValue179
      value:
        integer literal ConstantValue179: type=DT_Ext_stGBxCf, value=0
    ConstantValue181
      value:
        boolean literal ConstantValue181: type=DT_InjSys_bFuCutOff, value=false
    ConstantValue19
      value:
        integer literal ConstantValue19: type=DT_VSCtl_aVehPTPotMin, value=0
    ConstantValue199
      value:
        integer literal ConstantValue199: type=DT_TqCmp_tqCnvLoss, value=0
    ConstantValue201
      value:
        integer literal ConstantValue201: type=DT_TqCmp_tqSumLossCmp, value=0
    ConstantValue203
      value:
        integer literal ConstantValue203: type=DT_TqDem_tqCkEfc, value=0
    ConstantValue205
      value:
        integer literal ConstantValue205: type=DT_TqDem_tqCkEfcMax, value=0
    ConstantValue207
      value:
        integer literal ConstantValue207: type=DT_TqDem_tqCkEfcMin, value=0
    ConstantValue21
      value:
        integer literal ConstantValue21: type=DT_VSCtl_aVehPreCoVSCtlReq, value=0
    ConstantValue223
      value:
        integer literal ConstantValue223: type=DT_TqSys_tqCkEfcMinFeas, value=0
    ConstantValue225
      value:
        integer literal ConstantValue225: type=DT_TqSys_tqCkEfcReq, value=0
    ConstantValue227
      value:
        integer literal ConstantValue227: type=DT_TqSys_tqCkEngReal, value=0
    ConstantValue229
      value:
        integer literal ConstantValue229: type=DT_VSCtl_aVehReq, value=-10240
    ConstantValue231
      value:
        boolean literal ConstantValue231: type=DT_VSCtl_bAvlTqWhlPT_no3, value=false
    ConstantValue233
      value:
        boolean literal ConstantValue233: type=DT_VSCtl_bCtlEfc_tqCkEfcMax, value=false
    ConstantValue235
      value:
        boolean literal ConstantValue235: type=DT_VSCtl_bCtlEfc_tqWhlPTMax, value=false
    ConstantValue237
      value:
        integer literal ConstantValue237: type=DT_VSCtl_mVeh, value=1
    ConstantValue241
      value:
        integer literal ConstantValue241: type=DT_VSCtl_rdWhl, value=1
    ConstantValue243
      value:
        integer literal ConstantValue243: type=DT_VSCtl_spdVeh, value=0
    ConstantValue25
      value:
        boolean literal ConstantValue25: type=DT_VSCtl_bAvlTqWhlPT_no3, value=false
    ConstantValue251
      value:
        integer literal ConstantValue251: type=DT_VSCtl_tqWhlPTMax, value=0
    ConstantValue255
      value:
        integer literal ConstantValue255: type=DT_VSCtl_tqWhlPTMin, value=0
    ConstantValue259
      value:
        integer literal ConstantValue259: type=DT_VSCtl_tqWhlPTPotMax, value=0
    ConstantValue261
      value:
        integer literal ConstantValue261: type=DT_VSCtl_tqWhlPTPotMin, value=0
    ConstantValue267
      value:
        integer literal ConstantValue267: type=DT_VSCtl_tqWhlPotMaxRsvHiThd, value=0
    ConstantValue269
      value:
        integer literal ConstantValue269: type=DT_VSCtl_tqWhlPotMaxRsvLoThd, value=0
    ConstantValue271
      value:
        integer literal ConstantValue271: type=DT_VSCtl_tqWhlPotMinRsvHiThd, value=0
    ConstantValue273
      value:
        integer literal ConstantValue273: type=DT_VSCtl_tqWhlPotMinRsvLoThd, value=0
    ConstantValue283
      value:
        integer literal ConstantValue283: type=DT_Veh_spdVeh, value=0
    ConstantValue285
      value:
        boolean literal ConstantValue285: type=DT_Ext_bCtlCmdPTTqCf, value=false
    ConstantValue3
      value:
        integer literal ConstantValue3: type=DT_VSCtl_aVehPTDrvMinReqRaw, value=0
    ConstantValue37
      value:
        integer literal ConstantValue37: type=DT_VSCtl_mVeh, value=1
    ConstantValue49
      value:
        integer literal ConstantValue49: type=DT_VSCtl_rdWhl, value=1
    ConstantValue51
      value:
        integer literal ConstantValue51: type=DT_VSCtl_spdVeh, value=0
    ConstantValue53
      value:
        integer literal ConstantValue53: type=DT_VSCtl_stVSCtlInfo, value=0
    ConstantValue7
      value:
        integer literal ConstantValue7: type=DT_VSCtl_aVehPTLim, value=0
    ConstantValue77
      value:
        integer literal ConstantValue77: type=DT_VSCtl_tqWhlPTMax, value=0
    ConstantValue81
      value:
        integer literal ConstantValue81: type=DT_VSCtl_tqWhlPTMin, value=0
    ConstantValue85
      value:
        integer literal ConstantValue85: type=DT_VSCtl_tqWhlPTPotMax, value=0
    ConstantValue87
      value:
        integer literal ConstantValue87: type=DT_VSCtl_tqWhlPTPotMin, value=0
    ConstantValue9
      value:
        integer literal ConstantValue9: type=DT_VSCtl_aVehPTMax, value=0
  internal behavior IB_VSInfo: component=VSINFO
    timing event EV_VSInfo_004_TEV: mode-dependency=dependent-on-mode=[R_UCE_stWkuMainRelSt.RCD_stWkuMainRelSt.Invalid, R_UCE_stWkuMainRelSt.RCD_stWkuMainRelSt.PostMainWakeUp, R_UCE_stWkuMainRelSt.RCD_stWkuMainRelSt.PreMainWakeUp], start-on-event=RE_VSInfo_004_TEV, period=0.01
    timing event EV_VSInfo_002_TEV: mode-dependency=dependent-on-mode=[R_UCE_stWkuMainRelSt.RCD_stWkuMainRelSt.Invalid, R_UCE_stWkuMainRelSt.RCD_stWkuMainRelSt.PostMainWakeUp, R_UCE_stWkuMainRelSt.RCD_stWkuMainRelSt.PreMainWakeUp], start-on-event=RE_VSInfo_002_TEV, period=0.01
    mode switch event EV_VSInfo_001_MSE: start-on-event=RE_VSInfo_001_MSE, activation=ENTRY, mode=R_EcuM_CurrentMode.currentMode.RUN
    timing event EV_VSInfo_003_TEV: mode-dependency=dependent-on-mode=[R_UCE_stWkuMainRelSt.RCD_stWkuMainRelSt.Invalid, R_UCE_stWkuMainRelSt.RCD_stWkuMainRelSt.PostMainWakeUp, R_UCE_stWkuMainRelSt.RCD_stWkuMainRelSt.PreMainWakeUp], start-on-event=RE_VSInfo_003_TEV, period=0.04
    11 x inter runnable variable, all with sw-calibration-access=READ-WRITE, communication-approach=EXPLICIT:
      VSCtl_stGrdLkInfo: type=DT_VSCtl_stGrdLkInfo, init-value=C_UInt8_0293
      VSCtl_spdVehRef: type=DT_VSCtl_spdVehRef, init-value=C_UInt16_0307
      VSCtl_stPTInfo: type=DT_VSCtl_stPTInfo, init-value=C_UInt8_0301
      VSCtl_tqWhlPTPotMaxCtla_no1: type=DT_VSCtl_tqWhlPTPotMaxCtla_no1, init-value=C_SInt16_32000295
      VSCtl_aAero: type=DT_VSCtl_aAero, init-value=C_SInt16_0287
      VSCtl_stVehInfo: type=DT_VSCtl_stVehInfo, init-value=C_UInt8_0289
      VSCtl_tqWhlPTLim: type=DT_VSCtl_tqWhlPTLim, init-value=C_SInt16_m32000305
      VSCtl_tqWhlPTIni: type=DT_VSCtl_tqWhlPTIni, init-value=C_SInt16_0291
      VSCtl_tqWhlBrkEstim: type=DT_VSCtl_tqWhlBrkEstim, init-value=C_SInt16_0297
      VSCtl_tqWhlBrkReq: type=DT_VSCtl_tqWhlBrkReq, init-value=C_SInt16_0299
      VSCtl_stDiagSpdVeh: type=DT_VSCtl_stDiagSpdVeh, init-value=C_UInt8_0303
    4 x runnable:
      RE_VSInfo_002_TEV: read-variable=[VSCtl_stPTInfo, VSCtl_aAero], written-variable=[VSCtl_stPTInfo, VSCtl_tqWhlPTLim, VSCtl_tqWhlBrkEstim, VSCtl_spdVehRef, VSCtl_stDiagSpdVeh, VSCtl_tqWhlPTPotMaxCtla_no1, VSCtl_stGrdLkInfo, VSCtl_tqWhlBrkReq, VSCtl_tqWhlPTIni]
        75 x data receive point:
          dr_TqDem_tqWhlPTPreCoVSCtlReq: data-element=R_TqDem_tqWhlPTPreCoVSCtlReq.TqDem_tqWhlPTPreCoVSCtlReq
          dr_Ext_bRotSpdFrntWhlCf: data-element=R_Ext_bRotSpdFrntWhlCf.Ext_bRotSpdFrntWhlCf
          dr_VehEst_tqWhlPTRealEstim: data-element=R_VehEst_tqWhlPTRealEstim.VehEst_tqWhlPTRealEstim
          dr_VSCtl_tqWhlPotMaxRsvLoThd: data-element=R_VSCtl_tqWhlPotMaxRsvLoThd.VSCtl_tqWhlPotMaxRsvLoThd
          dr_Ext_stDVSRegCf: data-element=R_Ext_stDVSRegCf.Ext_stDVSRegCf
          dr_Ext_bDetLoWhlGripCf: data-element=R_Ext_bDetLoWhlGripCf.Ext_bDetLoWhlGripCf
          dr_TqCmp_tqSumLossCmp: data-element=R_TqCmp_tqSumLossCmp.TqCmp_tqSumLossCmp
          dr_VSCtl_rSlop: data-element=R_VSCtl_rSlop.VSCtl_rSlop
          dr_Ext_stPTCf: data-element=R_Ext_stPTCf.Ext_stPTCf
          dr_Ext_stGBxCf: data-element=R_Ext_stGBxCf.Ext_stGBxCf
          dr_VSCtl_tqWhlPotMinRsvHiThd: data-element=R_VSCtl_tqWhlPotMinRsvHiThd.VSCtl_tqWhlPotMinRsvHiThd
          dr_VSCtl_bCtlEfc_tqWhlPTMax: data-element=R_VSCtl_bCtlEfc_tqWhlPTMax.VSCtl_bCtlEfc_tqWhlPTMax
          dr_CoPTSt_stEng: data-element=R_CoPTSt_stEng.CoPTSt_stEng
          dr_PtLim_tqWhlPTMaxNotCtla: data-element=R_PtLim_tqWhlPTMaxNotCtla.PtLim_tqWhlPTMaxNotCtla
          dr_VehEst_bCtlTqWhlPT: data-element=R_VehEst_bCtlTqWhlPT.VehEst_bCtlTqWhlPT
          dr_VSCtl_rdWhl: data-element=R_VSCtl_rdWhl.VSCtl_rdWhl
          dr_TqDem_tqCkEfcMax: data-element=R_TqDem_tqCkEfcMax.TqDem_tqCkEfcMax
          dr_Ext_bVSMaxsCf: data-element=R_Ext_bVSMaxsCf.Ext_bVSMaxsCf
          dr_InjSys_bFuCutOff: data-element=R_InjSys_bFuCutOff.InjSys_bFuCutOff
          dr_PtLim_tqWhlThPTPotMin: data-element=R_PtLim_tqWhlThPTPotMin.PtLim_tqWhlThPTPotMin
          dr_TqSys_tqCkEngReal: data-element=R_TqSys_tqCkEngReal.TqSys_tqCkEngReal
          dr_VSCtl_mVeh: data-element=R_VSCtl_mVeh.VSCtl_mVeh
          dr_CoPt_noEgdGearCordIt: data-element=R_CoPt_noEgdGearCordIt.CoPt_noEgdGearCordIt
          dr_PtLim_tqWhlPTPotMinCtla: data-element=R_PtLim_tqWhlPTPotMinCtla.PtLim_tqWhlPTPotMinCtla
          dr_VSCtl_bCtlEfc_tqCkEfcMax: data-element=R_VSCtl_bCtlEfc_tqCkEfcMax.VSCtl_bCtlEfc_tqCkEfcMax
          dr_TqDem_tqWhlPTDrvMinReq: data-element=R_TqDem_tqWhlPTDrvMinReq.TqDem_tqWhlPTDrvMinReq
          dr_ECU_bAuthVSCtlIni: data-element=R_ECU_bAuthVSCtlIni.ECU_bAuthVSCtlIni
          dr_Ext_bAvlTqWhlPT_no3: data-element=R_Ext_bAvlTqWhlPT_no3.Ext_bAvlTqWhlPT_no3
          dr_CoPt_posnLev: data-element=R_CoPt_posnLev.CoPt_posnLev
          dr_Ext_bVSMaxfCf: data-element=R_Ext_bVSMaxfCf.Ext_bVSMaxfCf
          dr_VSCtl_tqWhlPotMinRsvLoThd: data-element=R_VSCtl_tqWhlPotMinRsvLoThd.VSCtl_tqWhlPotMinRsvLoThd
          dr_Ext_bRatConvTraCf: data-element=R_Ext_bRatConvTraCf.Ext_bRatConvTraCf
          dr_PtLim_tqWhlPTPotMaxCtla_no2: data-element=R_PtLim_tqWhlPTPotMaxCtla_no2.PtLim_tqWhlPTPotMaxCtla_no2
          dr_PtLim_tqWhlPTPotMaxCtla_no1: data-element=R_PtLim_tqWhlPTPotMaxCtla_no1.PtLim_tqWhlPTPotMaxCtla_no1
          dr_Ext_bAvlTqWhlPT_no1: data-element=R_Ext_bAvlTqWhlPT_no1.Ext_bAvlTqWhlPT_no1
          dr_CoPt_bSIPCord: data-element=R_CoPt_bSIPCord.CoPt_bSIPCord
          dr_PtLim_tqWhlPTMinCtla: data-element=R_PtLim_tqWhlPTMinCtla.PtLim_tqWhlPTMinCtla
          dr_Brk_tqWhlBrkReq: data-element=R_Brk_tqWhlBrkReq.Brk_tqWhlBrkReq
          dr_Ext_nEng: data-element=R_Ext_nEng.Ext_nEng
          dr_Ext_spdFrntWhl: data-element=R_Ext_spdFrntWhl.Ext_spdFrntWhl
          dr_TqDem_tqWhlPTDrvMaxReq: data-element=R_TqDem_tqWhlPTDrvMaxReq.TqDem_tqWhlPTDrvMaxReq
          dr_Ext_bDetLoWhlGrip: data-element=R_Ext_bDetLoWhlGrip.Ext_bDetLoWhlGrip
          dr_Ext_bSpdReWhlCf: data-element=R_Ext_bSpdReWhlCf.Ext_bSpdReWhlCf
          dr_TqDem_tqWhlPTPreCoVSCMaxReq: data-element=R_TqDem_tqWhlPTPreCoVSCMaxReq.TqDem_tqWhlPTPreCoVSCMaxReq
          dr_PtLim_tqWhlPTMinNotCtla: data-element=R_PtLim_tqWhlPTMinNotCtla.PtLim_tqWhlPTMinNotCtla
          dr_Ext_bSpdFrntWhlCf: data-element=R_Ext_bSpdFrntWhlCf.Ext_bSpdFrntWhlCf
          dr_VehEst_rTqWhlPTRe: data-element=R_VehEst_rTqWhlPTRe.VehEst_rTqWhlPTRe
          dr_TqSys_tqCkEfcReq: data-element=R_TqSys_tqCkEfcReq.TqSys_tqCkEfcReq
          dr_TqSys_tqCkEfcMinFeas: data-element=R_TqSys_tqCkEfcMinFeas.TqSys_tqCkEfcMinFeas
          dr_PtLim_tqWhlPTMaxCtla: data-element=R_PtLim_tqWhlPTMaxCtla.PtLim_tqWhlPTMaxCtla
          dr_TqDem_tqCkEfcMin: data-element=R_TqDem_tqCkEfcMin.TqDem_tqCkEfcMin
          dr_CoPt_rCnvTq: data-element=R_CoPt_rCnvTq.CoPt_rCnvTq
          DRP_R_Ext_bCtlCmdPTTqCf_Ext_bCtlCmdPTTqCf: data-element=R_Ext_bCtlCmdPTTqCf.Ext_bCtlCmdPTTqCf
          dr_Ext_bTqWhlBrkCf: data-element=R_Ext_bTqWhlBrkCf.Ext_bTqWhlBrkCf
          dr_Ext_bVSMaxpCf: data-element=R_Ext_bVSMaxpCf.Ext_bVSMaxpCf
          dr_Ext_bVSLimCf: data-element=R_Ext_bVSLimCf.Ext_bVSLimCf
          dr_VSCtl_spdVeh: data-element=R_VSCtl_spdVeh.VSCtl_spdVeh
          dr_CoPt_stClu: data-element=R_CoPt_stClu.CoPt_stClu
          dr_PtLim_tqWhlThPTMin: data-element=R_PtLim_tqWhlThPTMin.PtLim_tqWhlThPTMin
          dr_Veh_spdVeh: data-element=R_Veh_spdVeh.Veh_spdVeh
          dr_Brk_tqWhlBrkEstim: data-element=R_Brk_tqWhlBrkEstim.Brk_tqWhlBrkEstim
          dr_TqDem_tqWhlPTDrvMinReqRaw: data-element=R_TqDem_tqWhlPTDrvMinReqRaw.TqDem_tqWhlPTDrvMinReqRaw
          dr_TqCmp_tqCnvLoss: data-element=R_TqCmp_tqCnvLoss.TqCmp_tqCnvLoss
          dr_VehEst_tqWhlPTReq: data-element=R_VehEst_tqWhlPTReq.VehEst_tqWhlPTReq
          dr_TqDem_tqWhlPTPreCoVSCMinReq: data-element=R_TqDem_tqWhlPTPreCoVSCMinReq.TqDem_tqWhlPTPreCoVSCMinReq
          dr_TqDem_tqCkEfc: data-element=R_TqDem_tqCkEfc.TqDem_tqCkEfc
          dr_Ext_spdReWhl: data-element=R_Ext_spdReWhl.Ext_spdReWhl
          dr_Ext_nFrntWhl: data-element=R_Ext_nFrntWhl.Ext_nFrntWhl
          dr_EngLim_tqEfcMaxStatVehSpdCtl: data-element=R_EngLim_tqEfcMaxStatVehSpdCtl.EngLim_tqEfcMaxStatVehSpdCtl
          dr_VSCtl_rTqWhlPTRe: data-element=R_VSCtl_rTqWhlPTRe.VSCtl_rTqWhlPTRe
          dr_Ext_bPosnGBxCf: data-element=R_Ext_bPosnGBxCf.Ext_bPosnGBxCf
          dr_TqDem_tqWhlPTDrvReq: data-element=R_TqDem_tqWhlPTDrvReq.TqDem_tqWhlPTDrvReq
          dr_Ext_bCluPedPrss: data-element=R_Ext_bCluPedPrss.Ext_bCluPedPrss
          dr_Ext_bAvlTqWhlPT_no2: data-element=R_Ext_bAvlTqWhlPT_no2.Ext_bAvlTqWhlPT_no2
          dr_VSCtl_tqWhlPotMaxRsvHiThd: data-element=R_VSCtl_tqWhlPotMaxRsvHiThd.VSCtl_tqWhlPotMaxRsvHiThd
        40 x data send point:
          ds_VSCtl_tqWhlThPTPotMin: data-element=P_VSCtl_tqWhlThPTPotMin.VSCtl_tqWhlThPTPotMin
          ds_VSCtl_rConvTra: data-element=P_VSCtl_rConvTra.VSCtl_rConvTra
          ds_VSCtl_tqWhlPTReal: data-element=P_VSCtl_tqWhlPTReal.VSCtl_tqWhlPTReal
          ds_VSCtl_tqCkEfcDrvMaxReq: data-element=P_VSCtl_tqCkEfcDrvMaxReq.VSCtl_tqCkEfcDrvMaxReq
          ds_VSCtl_tqWhlPTPotRawMax: data-element=P_VSCtl_tqWhlPTPotRawMax.VSCtl_tqWhlPTPotRawMax
          ds_VSCtl_bAvlTqWhlPT_no3: data-element=P_VSCtl_bAvlTqWhlPT_no3.VSCtl_bAvlTqWhlPT_no3
          ds_VSCtl_grdRatConvTra: data-element=P_VSCtl_grdRatConvTra.VSCtl_grdRatConvTra
          ds_VSCtl_tqCkEfcPreCoVSCtlReq: data-element=P_VSCtl_tqCkEfcPreCoVSCtlReq.VSCtl_tqCkEfcPreCoVSCtlReq
          ds_VSCtl_tqWhlPTPotMin: data-element=P_VSCtl_tqWhlPTPotMin.VSCtl_tqWhlPTPotMin
          ds_VSCtl_tqWhlPTAplReq: data-element=P_VSCtl_tqWhlPTAplReq.VSCtl_tqWhlPTAplReq
          ds_VSCtl_tqWhlPTPotRawMin: data-element=P_VSCtl_tqWhlPTPotRawMin.VSCtl_tqWhlPTPotRawMin
          ds_VSCtl_rTqWhlPTDrvReq: data-element=P_VSCtl_rTqWhlPTDrvReq.VSCtl_rTqWhlPTDrvReq
          ds_VSCtl_tqWhlPTMin: data-element=P_VSCtl_tqWhlPTMin.VSCtl_tqWhlPTMin
          ds_VSCtl_bNbGearEgdChg: data-element=P_VSCtl_bNbGearEgdChg.VSCtl_bNbGearEgdChg
          ds_VSCtl_tqWhlPTDrvMaxReq: data-element=P_VSCtl_tqWhlPTDrvMaxReq.VSCtl_tqWhlPTDrvMaxReq
          ds_VSCtl_bAvlTqWhlPT_no2: data-element=P_VSCtl_bAvlTqWhlPT_no2.VSCtl_bAvlTqWhlPT_no2
          ds_VSCtl_rWhlSlip_no1: data-element=P_VSCtl_rWhlSlip_no1.VSCtl_rWhlSlip_no1
          ds_VSCtl_tqCkEfcMinNotCtla: data-element=P_VSCtl_tqCkEfcMinNotCtla.VSCtl_tqCkEfcMinNotCtla
          ds_VSCtl_tqWhlThPTMin: data-element=P_VSCtl_tqWhlThPTMin.VSCtl_tqWhlThPTMin
          ds_VSCtl_tqLossTra: data-element=P_VSCtl_tqLossTra.VSCtl_tqLossTra
          ds_VSCtl_tqWhlPTDrvMinReqRaw: data-element=P_VSCtl_tqWhlPTDrvMinReqRaw.VSCtl_tqWhlPTDrvMinReqRaw
          ds_VSCtl_rTqWhlPTRe: data-element=P_VSCtl_rTqWhlPTRe.VSCtl_rTqWhlPTRe
          ds_VSCtl_bCtlaTqPT: data-element=P_VSCtl_bCtlaTqPT.VSCtl_bCtlaTqPT
          ds_VSCtl_nEngFil: data-element=P_VSCtl_nEngFil.VSCtl_nEngFil
          ds_VSCtl_nFrntWhlFil: data-element=P_VSCtl_nFrntWhlFil.VSCtl_nFrntWhlFil
          ds_VSCtl_tqWhlPTPotMax: data-element=P_VSCtl_tqWhlPTPotMax.VSCtl_tqWhlPTPotMax
          ds_VSCtl_tqCkEfcMax: data-element=P_VSCtl_tqCkEfcMax.VSCtl_tqCkEfcMax
          ds_VSCtl_tqWhlPTMax: data-element=P_VSCtl_tqWhlPTMax.VSCtl_tqWhlPTMax
          ds_VSCtl_tqWhlPTPreCoVSCMaxReq: data-element=P_VSCtl_tqWhlPTPreCoVSCMaxReq.VSCtl_tqWhlPTPreCoVSCMaxReq
          ds_VSCtl_tqCkEfcPreCoVSCMinReq: data-element=P_VSCtl_tqCkEfcPreCoVSCMinReq.VSCtl_tqCkEfcPreCoVSCMinReq
          ds_VSCtl_bAvlTqWhlPT_no1: data-element=P_VSCtl_bAvlTqWhlPT_no1.VSCtl_bAvlTqWhlPT_no1
          ds_VSCtl_tqCkEfcDrvMinReq: data-element=P_VSCtl_tqCkEfcDrvMinReq.VSCtl_tqCkEfcDrvMinReq
          ds_VSCtl_tqWhlPTMinNotCtla: data-element=P_VSCtl_tqWhlPTMinNotCtla.VSCtl_tqWhlPTMinNotCtla
          ds_VSCtl_tqWhlPTPreCoVSCtlReq: data-element=P_VSCtl_tqWhlPTPreCoVSCtlReq.VSCtl_tqWhlPTPreCoVSCtlReq
          ds_VSCtl_rWhlSlip_no2: data-element=P_VSCtl_rWhlSlip_no2.VSCtl_rWhlSlip_no2
          ds_VSCtl_tqCkEfcMin: data-element=P_VSCtl_tqCkEfcMin.VSCtl_tqCkEfcMin
          ds_VSCtl_tqWhlPTPreCoVSCMinReq: data-element=P_VSCtl_tqWhlPTPreCoVSCMinReq.VSCtl_tqWhlPTPreCoVSCMinReq
          ds_VSCtl_tqWhlPTDrvMinReq: data-element=P_VSCtl_tqWhlPTDrvMinReq.VSCtl_tqWhlPTDrvMinReq
          ds_VSCtl_tqCkEfcMaxNotCtla: data-element=P_VSCtl_tqCkEfcMaxNotCtla.VSCtl_tqCkEfcMaxNotCtla
          ds_VSCtl_tqWhlPTMaxNotCtla: data-element=P_VSCtl_tqWhlPTMaxNotCtla.VSCtl_tqWhlPTMaxNotCtla
        19 x sync call:
          ssp_FRM_bDeacVSCtlLoWhlGripClc: operation=R_FRM_bDeacVSCtlLoWhlGripClc.GetFunctionPermission
          ssp_FRM_bRcvVSCtlrConvTra_Ext: operation=R_FRM_bRcvVSCtlrConvTra_Ext.GetFunctionPermission
          ssp_FRM_bDeacVSCtlrTqWhlPTReClc: operation=R_FRM_bDeacVSCtlrTqWhlPTReClc.GetFunctionPermission
          ssp_FRM_bDeacNFrntWhlClc: operation=R_FRM_bDeacNFrntWhlClc.GetFunctionPermission
          ssp_FRM_bDeacVSCtlWhlSlipClc: operation=R_FRM_bDeacVSCtlWhlSlipClc.GetFunctionPermission
          ssp_FRM_bDeacVSCtlGrdLkClc: operation=R_FRM_bDeacVSCtlGrdLkClc.GetFunctionPermission
          ssp_FRM_bDeacVSCtlBrkClc: operation=R_FRM_bDeacVSCtlBrkClc.GetFunctionPermission
          ssp_FRM_bDeacSpdVehClc: operation=R_FRM_bDeacSpdVehClc.GetFunctionPermission
          ssp_FRM_bDeacVSCtlTraClc: operation=R_FRM_bDeacVSCtlTraClc.GetFunctionPermission
          ssp_VSCtl_SpdVehClc: operation=R_VSCtl_SpdVehClc.SetEventStatus
          ssp_FRM_bRcvVSCtlrConvTra_Int1: operation=R_FRM_bRcvVSCtlrConvTra_Int1.GetFunctionPermission
          ssp_FRM_bDeacVSCtlPTClc: operation=R_FRM_bDeacVSCtlPTClc.GetFunctionPermission
          ssp_FRM_bDeacVSCtlNoGearChgClc: operation=R_FRM_bDeacVSCtlNoGearChgClc.GetFunctionPermission
          ssp_FRM_bRcvVSCtlSpdReWhl: operation=R_FRM_bRcvVSCtlSpdReWhl.GetFunctionPermission
          ssp_GetTimer_1ms_U32: operation=R_VSInfo_GetTimer_1ms_U32.GetTimer_1ms_U32
          ssp_VSCtl_RatConvTraClc: operation=R_VSCtl_RatConvTraClc.SetEventStatus
          ssp_FRM_bRcvVSCtlSpdFrntWhl: operation=R_FRM_bRcvVSCtlSpdFrntWhl.GetFunctionPermission
          ssp_FRM_bDeacVSCtlEngClc: operation=R_FRM_bDeacVSCtlEngClc.GetFunctionPermission
          ssp_FRM_bRcvVSCtlrConvTra_Int2: operation=R_FRM_bRcvVSCtlrConvTra_Int2.GetFunctionPermission
      RE_VSInfo_003_TEV: read-variable=[VSCtl_tqWhlBrkEstim, VSCtl_tqWhlPTLim, VSCtl_tqWhlPTPotMaxCtla_no1, VSCtl_tqWhlBrkReq, VSCtl_spdVehRef, VSCtl_tqWhlPTIni, VSCtl_stPTInfo, VSCtl_stGrdLkInfo], written-variable=[VSCtl_stVehInfo, VSCtl_aAero]
        20 x data receive point:
          dr_Ext_bBrkDynCf: data-element=R_Ext_bBrkDynCf.Ext_bBrkDynCf
          dr_VSCtl_aVehReq: data-element=R_VSCtl_aVehReq.VSCtl_aVehReq
          dr_VSCtl_tqWhlPTMinNotCtla: data-element=R_VSCtl_tqWhlPTMinNotCtla.VSCtl_tqWhlPTMinNotCtla
          dr_VSCtl_tqWhlPTMax: data-element=R_VSCtl_tqWhlPTMax.VSCtl_tqWhlPTMax
          dr_VSCtl_tqWhlPTAplReq: data-element=R_VSCtl_tqWhlPTAplReq.VSCtl_tqWhlPTAplReq
          dr_Ext_bBrkAutoCf: data-element=R_Ext_bBrkAutoCf.Ext_bBrkAutoCf
          dr_VSCtl_tqWhlPTDrvMinReqRaw: data-element=R_VSCtl_tqWhlPTDrvMinReqRaw.VSCtl_tqWhlPTDrvMinReqRaw
          dr_VSCtl_bAvlTqWhlPT_no3: data-element=R_VSCtl_bAvlTqWhlPT_no3.VSCtl_bAvlTqWhlPT_no3
          dr_VSCtl_tqWhlPTDrvMinReq: data-element=R_VSCtl_tqWhlPTDrvMinReq.VSCtl_tqWhlPTDrvMinReq
          dr_VSCtl_tqWhlPTPotMax: data-element=R_VSCtl_tqWhlPTPotMax.VSCtl_tqWhlPTPotMax
          dr_Ext_bBrkPedPrss: data-element=R_Ext_bBrkPedPrss.Ext_bBrkPedPrss
          dr_VSCtl_tqWhlPTMaxNotCtla: data-element=R_VSCtl_tqWhlPTMaxNotCtla.VSCtl_tqWhlPTMaxNotCtla
          dr_Brk_bBrkDyn: data-element=R_Brk_bBrkDyn.Brk_bBrkDyn
          dr_Ext_bPrkBrk: data-element=R_Ext_bPrkBrk.Ext_bPrkBrk
          dr_VSCtl_tqWhlPTPotMin: data-element=R_VSCtl_tqWhlPTPotMin.VSCtl_tqWhlPTPotMin
          dr_VSCtl_tqWhlPTReal: data-element=R_VSCtl_tqWhlPTReal.VSCtl_tqWhlPTReal
          dr_Brk_bBrkAuto: data-element=R_Brk_bBrkAuto.Brk_bBrkAuto
          dr_VSCtl_tqWhlPTMin: data-element=R_VSCtl_tqWhlPTMin.VSCtl_tqWhlPTMin
          dr_Ext_stGBxCf: data-element=R_Ext_stGBxCf.Ext_stGBxCf
          dr_VSCtl_tqWhlPTPreCoVSCtlReq: data-element=R_VSCtl_tqWhlPTPreCoVSCtlReq.VSCtl_tqWhlPTPreCoVSCtlReq
        20 x data send point:
          ds_VSCtl_aVehPTDrvMinReqRaw: data-element=P_VSCtl_aVehPTDrvMinReqRaw.VSCtl_aVehPTDrvMinReqRaw
          ds_VSCtl_aVehPTPotMaxCtla_no1: data-element=P_VSCtl_aVehPTPotMaxCtla_no1.VSCtl_aVehPTPotMaxCtla_no1
          ds_VSCtl_aVehPTLim: data-element=P_VSCtl_aVehPTLim.VSCtl_aVehPTLim
          ds_VSCtl_aVeh: data-element=P_VSCtl_aVeh.VSCtl_aVeh
          ds_VSCtl_spdVeh: data-element=P_VSCtl_spdVeh.VSCtl_spdVeh
          ds_VSCtl_mVeh: data-element=P_VSCtl_mVeh.VSCtl_mVeh
          ds_VSCtl_bLgtCtlDyn: data-element=P_VSCtl_bLgtCtlDyn.VSCtl_bLgtCtlDyn
          ds_VSCtl_aVehPTPotMax: data-element=P_VSCtl_aVehPTPotMax.VSCtl_aVehPTPotMax
          ds_VSCtl_aRes: data-element=P_VSCtl_aRes.VSCtl_aRes
          ds_VSCtl_aVehPTMinNotCtla: data-element=P_VSCtl_aVehPTMinNotCtla.VSCtl_aVehPTMinNotCtla
          ds_VSCtl_jrkVeh: data-element=P_VSCtl_jrkVeh.VSCtl_jrkVeh
          ds_VSCtl_aVehPTMin: data-element=P_VSCtl_aVehPTMin.VSCtl_aVehPTMin
          ds_VSCtl_aVehPreCoVSCtlReq: data-element=P_VSCtl_aVehPreCoVSCtlReq.VSCtl_aVehPreCoVSCtlReq
          ds_VSCtl_rSlop: data-element=P_VSCtl_rSlop.VSCtl_rSlop
          ds_VSCtl_aVehPTMax: data-element=P_VSCtl_aVehPTMax.VSCtl_aVehPTMax
          ds_VSCtl_aVehPTIni: data-element=P_VSCtl_aVehPTIni.VSCtl_aVehPTIni
          ds_VSCtl_rdWhl: data-element=P_VSCtl_rdWhl.VSCtl_rdWhl
          ds_VSCtl_aVehPTPotMin: data-element=P_VSCtl_aVehPTPotMin.VSCtl_aVehPTPotMin
          ds_VSCtl_aVehPTDrvMinReq: data-element=P_VSCtl_aVehPTDrvMinReq.VSCtl_aVehPTDrvMinReq
          ds_VSCtl_aVehPTMaxNotCtla: data-element=P_VSCtl_aVehPTMaxNotCtla.VSCtl_aVehPTMaxNotCtla
        sync call ssp_GetTimer_1ms_U32: operation=R_VSInfo_GetTimer_1ms_U32.GetTimer_1ms_U32
        sync call ssp_FRM_bDeacVSCtlVehClc: operation=R_FRM_bDeacVSCtlVehClc.GetFunctionPermission
      RE_VSInfo_001_MSE: written-variable=[VSCtl_aAero, VSCtl_stGrdLkInfo, VSCtl_tqWhlPTLim, VSCtl_tqWhlBrkEstim, VSCtl_tqWhlPTIni, VSCtl_stDiagSpdVeh, VSCtl_stVehInfo, VSCtl_stPTInfo, VSCtl_spdVehRef, VSCtl_tqWhlBrkReq, VSCtl_tqWhlPTPotMaxCtla_no1]
        62 x data send point:
          ds_VSCtl_tqWhlThPTPotMin: data-element=P_VSCtl_tqWhlThPTPotMin.VSCtl_tqWhlThPTPotMin
          ds_VSCtl_bAvlTqWhlPT_no1: data-element=P_VSCtl_bAvlTqWhlPT_no1.VSCtl_bAvlTqWhlPT_no1
          ds_VSCtl_nFrntWhlFil: data-element=P_VSCtl_nFrntWhlFil.VSCtl_nFrntWhlFil
          ds_VSCtl_tqWhlPTPotMax: data-element=P_VSCtl_tqWhlPTPotMax.VSCtl_tqWhlPTPotMax
          ds_VSCtl_tqWhlPTDrvMinReqRaw: data-element=P_VSCtl_tqWhlPTDrvMinReqRaw.VSCtl_tqWhlPTDrvMinReqRaw
          ds_VSCtl_aRes: data-element=P_VSCtl_aRes.VSCtl_aRes
          ds_VSCtl_tqCkEfcPreCoVSCMinReq: data-element=P_VSCtl_tqCkEfcPreCoVSCMinReq.VSCtl_tqCkEfcPreCoVSCMinReq
          ds_VSCtl_spdVeh: data-element=P_VSCtl_spdVeh.VSCtl_spdVeh
          ds_VSCtl_tqWhlPTPotMin: data-element=P_VSCtl_tqWhlPTPotMin.VSCtl_tqWhlPTPotMin
          ds_VSCtl_bAvlTqWhlPT_no2: data-element=P_VSCtl_bAvlTqWhlPT_no2.VSCtl_bAvlTqWhlPT_no2
          ds_VSCtl_aVehPreCoVSCtlReq: data-element=P_VSCtl_aVehPreCoVSCtlReq.VSCtl_aVehPreCoVSCtlReq
          ds_VSCtl_aVehPTDrvMinReqRaw: data-element=P_VSCtl_aVehPTDrvMinReqRaw.VSCtl_aVehPTDrvMinReqRaw
          ds_VSCtl_aVehPTDrvMinReq: data-element=P_VSCtl_aVehPTDrvMinReq.VSCtl_aVehPTDrvMinReq
          ds_VSCtl_tqWhlPTPreCoVSCMaxReq: data-element=P_VSCtl_tqWhlPTPreCoVSCMaxReq.VSCtl_tqWhlPTPreCoVSCMaxReq
          ds_VSCtl_jrkVeh: data-element=P_VSCtl_jrkVeh.VSCtl_jrkVeh
          ds_VSCtl_tqCkEfcDrvMaxReq: data-element=P_VSCtl_tqCkEfcDrvMaxReq.VSCtl_tqCkEfcDrvMaxReq
          ds_VSCtl_mVeh: data-element=P_VSCtl_mVeh.VSCtl_mVeh
          ds_VSCtl_tqWhlPTDrvMinReq: data-element=P_VSCtl_tqWhlPTDrvMinReq.VSCtl_tqWhlPTDrvMinReq
          ds_VSCtl_aVehPTPotMaxCtla_no1: data-element=P_VSCtl_aVehPTPotMaxCtla_no1.VSCtl_aVehPTPotMaxCtla_no1
          ds_VSCtl_aVeh: data-element=P_VSCtl_aVeh.VSCtl_aVeh
          ds_VSCtl_aVehPTMaxNotCtla: data-element=P_VSCtl_aVehPTMaxNotCtla.VSCtl_aVehPTMaxNotCtla
          ds_VSCtl_bNbGearEgdChg: data-element=P_VSCtl_bNbGearEgdChg.VSCtl_bNbGearEgdChg
          ds_VSCtl_tqCkEfcMinNotCtla: data-element=P_VSCtl_tqCkEfcMinNotCtla.VSCtl_tqCkEfcMinNotCtla
          ds_VSCtl_bLgtCtlDyn: data-element=P_VSCtl_bLgtCtlDyn.VSCtl_bLgtCtlDyn
          ds_VSCtl_nEngFil: data-element=P_VSCtl_nEngFil.VSCtl_nEngFil
          ds_VSCtl_rConvTra: data-element=P_VSCtl_rConvTra.VSCtl_rConvTra
          ds_VSCtl_bCtlaTqPT: data-element=P_VSCtl_bCtlaTqPT.VSCtl_bCtlaTqPT
          ds_VSCtl_aVehPTMax: data-element=P_VSCtl_aVehPTMax.VSCtl_aVehPTMax
          ds_VSCtl_tqWhlThPTMin: data-element=P_VSCtl_tqWhlThPTMin.VSCtl_tqWhlThPTMin
          ds_VSCtl_tqWhlPTMax: data-element=P_VSCtl_tqWhlPTMax.VSCtl_tqWhlPTMax
          ds_VSCtl_rTqWhlPTRe: data-element=P_VSCtl_rTqWhlPTRe.VSCtl_rTqWhlPTRe
          ds_VSCtl_aVehPTPotMin: data-element=P_VSCtl_aVehPTPotMin.VSCtl_aVehPTPotMin
          ds_VSCtl_tqCkEfcMin: data-element=P_VSCtl_tqCkEfcMin.VSCtl_tqCkEfcMin
          ds_VSCtl_rdWhl: data-element=P_VSCtl_rdWhl.VSCtl_rdWhl
          ds_VSCtl_aVehPTMinNotCtla: data-element=P_VSCtl_aVehPTMinNotCtla.VSCtl_aVehPTMinNotCtla
          ds_VSCtl_bAvlTqWhlPT_no3: data-element=P_VSCtl_bAvlTqWhlPT_no3.VSCtl_bAvlTqWhlPT_no3
          ds_VSCtl_rSlop: data-element=P_VSCtl_rSlop.VSCtl_rSlop
          ds_VSCtl_grdRatConvTra: data-element=P_VSCtl_grdRatConvTra.VSCtl_grdRatConvTra
          ds_VSCtl_tqWhlPTPreCoVSCtlReq: data-element=P_VSCtl_tqWhlPTPreCoVSCtlReq.VSCtl_tqWhlPTPreCoVSCtlReq
          ds_VSCtl_tqLossTra: data-element=P_VSCtl_tqLossTra.VSCtl_tqLossTra
          ds_VSCtl_tqCkEfcMaxNotCtla: data-element=P_VSCtl_tqCkEfcMaxNotCtla.VSCtl_tqCkEfcMaxNotCtla
          ds_VSCtl_tqWhlPTMin: data-element=P_VSCtl_tqWhlPTMin.VSCtl_tqWhlPTMin
          ds_VSCtl_rWhlSlip_no1: data-element=P_VSCtl_rWhlSlip_no1.VSCtl_rWhlSlip_no1
          ds_VSCtl_aVehPTPotMax: data-element=P_VSCtl_aVehPTPotMax.VSCtl_aVehPTPotMax
          ds_VSCtl_rTqWhlPTDrvReq: data-element=P_VSCtl_rTqWhlPTDrvReq.VSCtl_rTqWhlPTDrvReq
          ds_VSCtl_tqCkEfcDrvMinReq: data-element=P_VSCtl_tqCkEfcDrvMinReq.VSCtl_tqCkEfcDrvMinReq
          ds_VSCtl_stVSCtlInfo: data-element=P_VSCtl_stVSCtlInfo.VSCtl_stVSCtlInfo
          ds_VSCtl_tqWhlPTReal: data-element=P_VSCtl_tqWhlPTReal.VSCtl_tqWhlPTReal
          ds_VSCtl_aVehPTIni: data-element=P_VSCtl_aVehPTIni.VSCtl_aVehPTIni
          ds_VSCtl_tqWhlPTAplReq: data-element=P_VSCtl_tqWhlPTAplReq.VSCtl_tqWhlPTAplReq
          ds_VSCtl_stDeacVSCtlInfo: data-element=P_VSCtl_stDeacVSCtlInfo.VSCtl_stDeacVSCtlInfo
          ds_VSCtl_tqWhlPTPotRawMin: data-element=P_VSCtl_tqWhlPTPotRawMin.VSCtl_tqWhlPTPotRawMin
          ds_VSCtl_rWhlSlip_no2: data-element=P_VSCtl_rWhlSlip_no2.VSCtl_rWhlSlip_no2
          ds_VSCtl_tqWhlPTMaxNotCtla: data-element=P_VSCtl_tqWhlPTMaxNotCtla.VSCtl_tqWhlPTMaxNotCtla
          ds_VSCtl_aVehPTLim: data-element=P_VSCtl_aVehPTLim.VSCtl_aVehPTLim
          ds_VSCtl_tqWhlPTPreCoVSCMinReq: data-element=P_VSCtl_tqWhlPTPreCoVSCMinReq.VSCtl_tqWhlPTPreCoVSCMinReq
          ds_VSCtl_tqCkEfcMax: data-element=P_VSCtl_tqCkEfcMax.VSCtl_tqCkEfcMax
          ds_VSCtl_tqCkEfcPreCoVSCtlReq: data-element=P_VSCtl_tqCkEfcPreCoVSCtlReq.VSCtl_tqCkEfcPreCoVSCtlReq
          ds_VSCtl_tqWhlPTPotRawMax: data-element=P_VSCtl_tqWhlPTPotRawMax.VSCtl_tqWhlPTPotRawMax
          ds_VSCtl_aVehPTMin: data-element=P_VSCtl_aVehPTMin.VSCtl_aVehPTMin
          ds_VSCtl_tqWhlPTDrvMaxReq: data-element=P_VSCtl_tqWhlPTDrvMaxReq.VSCtl_tqWhlPTDrvMaxReq
          ds_VSCtl_tqWhlPTMinNotCtla: data-element=P_VSCtl_tqWhlPTMinNotCtla.VSCtl_tqWhlPTMinNotCtla
        sync call ssp_GetTimer_1ms_U32: operation=R_VSInfo_GetTimer_1ms_U32.GetTimer_1ms_U32
      RE_VSInfo_004_TEV: read-variable=[VSCtl_stVehInfo, VSCtl_stDiagSpdVeh, VSCtl_stPTInfo]
        data send point ds_VSCtl_stDeacVSCtlInfo: data-element=P_VSCtl_stDeacVSCtlInfo.VSCtl_stDeacVSCtlInfo
        data send point ds_VSCtl_stVSCtlInfo: data-element=P_VSCtl_stVSCtlInfo.VSCtl_stVSCtlInfo
        6 x sync call:
          ssp_FRM_bDeacVSCtlGrdLkClc: operation=R_FRM_bDeacVSCtlGrdLkClc.GetFunctionPermission
          ssp_FRM_bDeacVSCtlPTClc: operation=R_FRM_bDeacVSCtlPTClc.GetFunctionPermission
          ssp_GetTimer_1ms_U32: operation=R_VSInfo_GetTimer_1ms_U32.GetTimer_1ms_U32
          ssp_FRM_bDeacVSCtlTraClc: operation=R_FRM_bDeacVSCtlTraClc.GetFunctionPermission
          ssp_FRM_bDeacVSCtlEngClc: operation=R_FRM_bDeacVSCtlEngClc.GetFunctionPermission
          ssp_FRM_bDeacVSCtlVehClc: operation=R_FRM_bDeacVSCtlVehClc.GetFunctionPermission
  swc implementation Imp_VSInfo: programming-language=C, behavior=IB_VSInfo
    code-descriptors:
      code CodeDescriptor: type=SRC
        20 x xfile:
          VSINFO_Available_Tq_Gmp1_Sl_c: url=VSINFO_Available_Tq_Gmp1_Sl.c
          VSINFO_Elabor_Info_Gmp2_Sl_c: url=VSINFO_Elabor_Info_Gmp2_Sl.c
          VSInfo_MemMap_h: url=VSInfo_MemMap.h
          VSINFO_Elabor_Repair_Req_Sl_c: url=VSINFO_Elabor_Repair_Req_Sl.c
          VSINFO_Ela_Gmp1_Re002tev_Sf_c: url=VSINFO_Ela_Gmp1_Re002tev_Sf.c
          VSINFO_Re003tev_Sf_c: url=VSINFO_Re003tev_Sf.c
          VSInfo_c: url=VSInfo.c
          VSINFO_Elabor_Info_Las_Sl_c: url=VSINFO_Elabor_Info_Las_Sl.c
          VSINFO_Elabor_Car_Info_Sl_c: url=VSINFO_Elabor_Car_Info_Sl.c
          VSINFO_Info_Transmission_Sl_c: url=VSINFO_Info_Transmission_Sl.c
          VSINFO_Speed_Estim_c: url=VSINFO_Speed_Estim.c
          VSINFO_Inf_Mnt_Re002tev_Sf_c: url=VSINFO_Inf_Mnt_Re002tev_Sf.c
          VSINFO_Wheel_Info_Gmp1_Sl_c: url=VSINFO_Wheel_Info_Gmp1_Sl.c
          VSINFO_Elabor_Info_Gmp_Sl_c: url=VSINFO_Elabor_Info_Gmp_Sl.c
          VSINFO_Accel_Estim_c: url=VSINFO_Accel_Estim.c
          VSINFO_Elabor_Info_Brake_Sl_c: url=VSINFO_Elabor_Info_Brake_Sl.c
          VSInfo_h: url=VSInfo.h
          VSINFO_Ela_Gmp2_Re002tev_Sf_c: url=VSINFO_Ela_Gmp2_Re002tev_Sf.c
          VSINFO_Elabor_State_Info_Sf_c: url=VSINFO_Elabor_State_Info_Sf.c
          VSINFO_Get_Info_Gmp2_Sl_c: url=VSINFO_Get_Info_Gmp2_Sl.c
package /Components/SWC_VSInfo/VSInfo_IRVDatatypes
  11 x integer type:
    DT_VSCtl_aAero: base-type=int16, lower-limit=-32768, upper-limit=32767
    DT_VSCtl_spdVehRef: base-type=uint16, lower-limit=0, upper-limit=65535
    DT_VSCtl_stDiagSpdVeh: base-type=uint8, lower-limit=0, upper-limit=255
    DT_VSCtl_stGrdLkInfo: base-type=uint8, lower-limit=0, upper-limit=255
    DT_VSCtl_stPTInfo: base-type=uint8, lower-limit=0, upper-limit=255
    DT_VSCtl_stVehInfo: base-type=uint8, lower-limit=0, upper-limit=255
    DT_VSCtl_tqWhlBrkEstim: base-type=int16, lower-limit=-32768, upper-limit=32767
    DT_VSCtl_tqWhlBrkReq: base-type=int16, lower-limit=-32768, upper-limit=32767
    DT_VSCtl_tqWhlPTIni: base-type=int16, lower-limit=-32768, upper-limit=32767
    DT_VSCtl_tqWhlPTLim: base-type=int16, lower-limit=-32768, upper-limit=32767
    DT_VSCtl_tqWhlPTPotMaxCtla_no1: base-type=int16, lower-limit=-32768, upper-limit=32767
